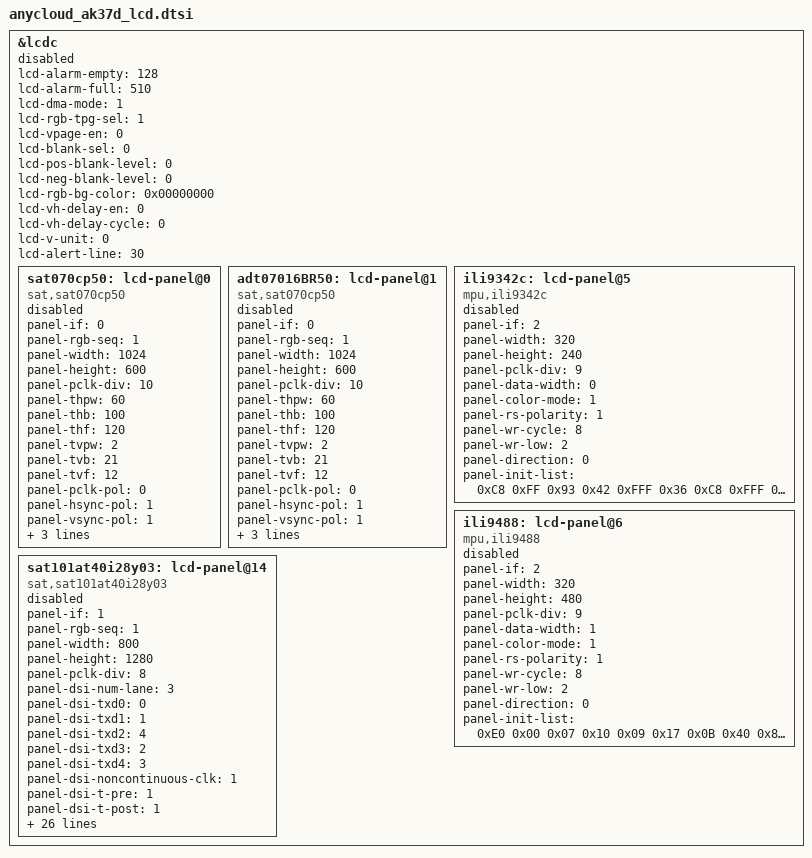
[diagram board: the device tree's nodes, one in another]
/*
 * AK37D LCD panel dts
 *
 * Copyright (C) 2018 Anyka(Guangzhou) Microelectronics Technology Co., Ltd.
 *
 * Author: Feilong Dong <dong_feilong@anyka.com>
 *
 * This program is free software; you can redistribute it and/or modify
 * it under the terms of the GNU General Public License as published by
 * the Free Software Foundation; either version 2 of the License, or
 * (at your option) any later version.
 *
 * This program is distributed in the hope that it will be useful,
 * but WITHOUT ANY WARRANTY; without even the implied warranty of
 * MERCHANTABILITY or FITNESS FOR A PARTICULAR PURPOSE.  See the
 * GNU General Public License for more details.
 */

&lcdc {
    lcd-alarm-empty = <128>;
    lcd-alarm-full = <510>;
    lcd-dma-mode = <1>;
    //lcd-dummy-seq = <0>; //for 8bit rgb panel set
    //lcd-rgb-seq-sel = <0>;
    //lcd-rgb-odd-seq = <0>;
    //lcd-rgb-even-seq = <0>;
    lcd-rgb-tpg-sel = <1>;
    lcd-vpage-en = <0>; //don't support vpage function in driver
    lcd-blank-sel = <0>;
    lcd-pos-blank-level = <0>;
    lcd-neg-blank-level = <0>;
    lcd-rgb-bg-color = <0x00000000>;
    lcd-vh-delay-en = <0>;
    lcd-vh-delay-cycle = <0>;
    lcd-v-unit = <0>;
    lcd-alert-line = <30>;
    status = "disable";
    
    sat070cp50: lcd-panel@0 { //for RGB panel setting
        compatible = "sat,sat070cp50";
        panel-if = <0>; //0 for RGB, 1 for MIPI, 2 for MPU
        panel-rgb-seq = <1>; //0 for BGR, 1 for RGB
        panel-width = <1024>;
        panel-height = <600>;
        panel-pclk-div = <10>; //pixel clock = Peri_pll/(pclk_div+1)
        panel-thpw = <60>;
        panel-thb = <100>;
        panel-thf = <120>;
        panel-tvpw = <2>;
        panel-tvb = <21>;
        panel-tvf = <12>;
        panel-pclk-pol = <0>; //0:pos, 1:neg
        panel-hsync-pol = <1>;
        panel-vsync-pol = <1>;
        panel-vogate-pol = <0>;
        panel-bus-width = <3>; //0:8bits,1:16bits,2:18bits,3:24bits
        panel-sync-mode = <1>; 

        status = "disable";
    };

    adt07016BR50: lcd-panel@1 { //for AJB RGB panel setting
        compatible = "sat,sat070cp50";
        panel-if = <0>; //0 for RGB, 1 for MIPI, 2 for MPU
        panel-rgb-seq = <1>; //0 for BGR, 1 for RGB
        panel-width = <1024>;
        panel-height = <600>;
        panel-pclk-div = <10>; //pixel clock = Peri_pll/(pclk_div+1)
        panel-thpw = <60>;
        panel-thb = <100>;
        panel-thf = <120>;
        panel-tvpw = <2>;
        panel-tvb = <21>;
        panel-tvf = <12>;
        panel-pclk-pol = <0>; //0:pos, 1:neg
        panel-hsync-pol = <1>;
        panel-vsync-pol = <1>;
        panel-vogate-pol = <0>;
        panel-bus-width = <3>; //0:8bits,1:16bits,2:18bits,3:24bits
        panel-sync-mode = <1>; 

        status = "disable";
    };

 /*
	//old mipi display
    sat101cp40: lcd-panel@2 { //for JD9365 MIPI panel setting
        compatible = "sat,sat101cp40";
        panel-if = <1>; //0 for RGB, 1 for MIPI, 2 for MPU
        panel-rgb-seq = <1>; //0 for BGR, 1 for RGB
        panel-width = <800>;
        panel-height = <1280>;
        panel-pclk-div = <8>; //pixel clock = Peri_pll/(pclk_div+1)
        panel-dsi-num-lane = <3>; //0-3: 1lane-4lane
        //0-3: data0-data3, 4: clk
        panel-dsi-txd0 = <0>;
        panel-dsi-txd1 = <1>;
        panel-dsi-txd2 = <4>;
        panel-dsi-txd3 = <2>;
        panel-dsi-txd4 = <3>;
        panel-dsi-noncontinuous-clk = <0>; //0:continuous,1:noncontinuous
        panel-dsi-t-pre = <1>; //t-pre, >=1
        panel-dsi-t-post = <1>; //t-post=tlpx+t-prepare+t-zero+t-pre, >=1
        panel-dsi-tx-gap = <1>; //ths-exit
        panel-dsi-autoinsert-eotp = <0>; //0:not insert,1:auto-insert
        panel-dsi-htx-to-count = <0xFFFFFF>; //high speed TX timeout count
        panel-dsi-lrx-to-count = <0xFFFFFF>; //Low power RX timeout count
        panel-dsi-bta-to-count = <0xFFFFFF>; //Bus turn around timeout count
        panel-dsi-t-wakeup = <0xc8>; //DPHY T-wakeup time
        panel-dsi-pix-fifo-send-level = <512>; //buffer send level <= 512
        //0-2:16-bit config 1-3; 3-4:18-bit config 1-2; 5:24-bit
        panel-dsi-if-color-coding = <0x05>;
        //0:16-bit;1:18-bit;2:18-bit loosely packed;3:24-bit
        panel-dsi-pix-format = <0x03>;
        panel-dsi-vsync-pol = <0>; //0:active low; 1:active high
        panel-dsi-hsync-pol = <0>; //0:active low; 1:active high
        //0:Non-burst mode with sync pulses;
        //1:Noe-burst mode with sync events;
        //2:Burst mode; 3:reserved
        panel-dsi-video-mode = <2>;
        panel-dsi-hfp = <40>; //H front porch blanking packet payload size in bytes
        panel-dsi-hbp = <20>; //H back porch blanking packet payload size in bytes
        panel-dsi-hsa = <20>; //H sync width blanking packet payload size in bytes
        panel-dsi-mult-pkts-en = <0>; //0: single packet;1: two packets
        panel-dsi-vbp = <8>; //V back porch lines
        panel-dsi-vfp = <8>; //V front porch lines
        panel-dsi-vsa = <4>;
        //0:blanking packets send during BLLP;1:LP mode used for BLLP
        panel-dsi-bllp-mode = <1>;
        panel-dsi-use-null-pkt-bllp = <0>; //0:blanking packet; 1:Null packet
        panel-dsi-vc = <0x00>; //Virtual channel
        panel-dsi-cmd-type = <0x0>; //0:send in LP mode, 1:send in HS mode
        panel-dsi-clk = <600>;
        //add special config list here
        panel-init-list =  //delay, type, data, parameters, end symbol
                          < 0x00 0x15 0xE0 0x00 0xFFF
                            0x00 0x15 0xE1 0x93 0xFFF
                            0x00 0x15 0xE2 0x65 0xFFF
                            0x00 0x15 0xE3 0xF8 0xFFF
                            0x00 0x15 0x80 0x03 0xFFF
                            0x00 0x15 0xE0 0x01 0xFFF
                            0x00 0x15 0x00 0x00 0xFFF
                            0x00 0x15 0x01 0x65 0xFFF
                            0x00 0x15 0x17 0x00 0xFFF
                            0x00 0x15 0x18 0xAF 0xFFF
                            0x00 0x15 0x19 0x01 0xFFF
                            0x00 0x15 0x1A 0x00 0xFFF
                            0x00 0x15 0x1B 0xAF 0xFFF
                            0x00 0x15 0x1C 0x01 0xFFF
                            0x00 0x15 0x1F 0x3E 0xFFF
                            0x00 0x15 0x20 0x28 0xFFF
                            0x00 0x15 0x21 0x28 0xFFF
                            0x00 0x15 0x22 0x7E 0xFFF
                            0x00 0x15 0x35 0x2A 0xFFF
                            0x00 0x15 0x37 0x09 0xFFF
                            0x00 0x15 0x38 0x04 0xFFF
                            0x00 0x15 0x39 0x00 0xFFF
                            0x00 0x15 0x3A 0x01 0xFFF
                            0x00 0x15 0x3C 0x76 0xFFF
                            0x00 0x15 0x3D 0xFF 0xFFF
                            0x00 0x15 0x3E 0xFF 0xFFF
                            0x00 0x15 0x3F 0x7F 0xFFF
                            0x00 0x15 0x40 0x06 0xFFF
                            0x00 0x15 0x41 0xA0 0xFFF
                            0x00 0x15 0x42 0x81 0xFFF
                            0x00 0x15 0x43 0x14 0xFFF
                            0x00 0x15 0x44 0x0A 0xFFF
                            0x00 0x15 0x45 0x12 0xFFF
                            0x00 0x15 0x55 0x01 0xFFF
                            0x00 0x15 0x56 0x01 0xFFF
                            0x00 0x15 0x57 0x6E 0xFFF
                            0x00 0x15 0x58 0x07 0xFFF
                            0x00 0x15 0x59 0x07 0xFFF
                            0x00 0x15 0x5A 0x29 0xFFF
                            0x00 0x15 0x5B 0x24 0xFFF
                            0x00 0x15 0x5D 0x7C 0xFFF
                            0x00 0x15 0x5E 0x65 0xFFF
                            0x00 0x15 0x5F 0x57 0xFFF
                            0x00 0x15 0x60 0x4A 0xFFF
                            0x00 0x15 0x61 0x46 0xFFF
                            0x00 0x15 0x62 0x36 0xFFF
                            0x00 0x15 0x63 0x3A 0xFFF
                            0x00 0x15 0x64 0x23 0xFFF
                            0x00 0x15 0x65 0x3A 0xFFF
                            0x00 0x15 0x66 0x38 0xFFF
                            0x00 0x15 0x67 0x38 0xFFF
                            0x00 0x15 0x68 0x55 0xFFF
                            0x00 0x15 0x69 0x43 0xFFF
                            0x00 0x15 0x6A 0x4A 0xFFF
                            0x00 0x15 0x6B 0x3B 0xFFF
                            0x00 0x15 0x6C 0x36 0xFFF
                            0x00 0x15 0x6D 0x28 0xFFF
                            0x00 0x15 0x6E 0x15 0xFFF
                            0x00 0x15 0x6F 0x00 0xFFF
                            0x00 0x15 0x70 0x7C 0xFFF
                            0x00 0x15 0x71 0x66 0xFFF
                            0x00 0x15 0x72 0x57 0xFFF
                            0x00 0x15 0x73 0x4A 0xFFF
                            0x00 0x15 0x74 0x46 0xFFF
                            0x00 0x15 0x75 0x36 0xFFF
                            0x00 0x15 0x76 0x3A 0xFFF
                            0x00 0x15 0x77 0x23 0xFFF
                            0x00 0x15 0x78 0x3A 0xFFF
                            0x00 0x15 0x79 0x38 0xFFF
                            0x00 0x15 0x7A 0x38 0xFFF
                            0x00 0x15 0x7B 0x55 0xFFF
                            0x00 0x15 0x7C 0x43 0xFFF
                            0x00 0x15 0x7D 0x4A 0xFFF
                            0x00 0x15 0x7E 0x3B 0xFFF
                            0x00 0x15 0x7F 0x36 0xFFF
                            0x00 0x15 0x80 0x28 0xFFF
                            0x00 0x15 0x81 0x15 0xFFF
                            0x00 0x15 0x82 0x00 0xFFF
                            0x00 0x15 0xE0 0x02 0xFFF
                            0x00 0x15 0x00 0x1E 0xFFF
                            0x00 0x15 0x01 0x1E 0xFFF
                            0x00 0x15 0x02 0x41 0xFFF
                            0x00 0x15 0x03 0x41 0xFFF
                            0x00 0x15 0x04 0x43 0xFFF
                            0x00 0x15 0x05 0x43 0xFFF
                            0x00 0x15 0x06 0x1F 0xFFF
                            0x00 0x15 0x07 0x1F 0xFFF
                            0x00 0x15 0x08 0x1F 0xFFF
                            0x00 0x15 0x09 0x1F 0xFFF
                            0x00 0x15 0x0A 0x1E 0xFFF
                            0x00 0x15 0x0B 0x1E 0xFFF
                            0x00 0x15 0x0C 0x1F 0xFFF
                            0x00 0x15 0x0D 0x47 0xFFF
                            0x00 0x15 0x0E 0x47 0xFFF
                            0x00 0x15 0x0F 0x45 0xFFF
                            0x00 0x15 0x10 0x45 0xFFF
                            0x00 0x15 0x11 0x4B 0xFFF
                            0x00 0x15 0x12 0x4B 0xFFF
                            0x00 0x15 0x13 0x49 0xFFF
                            0x00 0x15 0x14 0x49 0xFFF
                            0x00 0x15 0x15 0x1F 0xFFF
                            0x00 0x15 0x16 0x1E 0xFFF
                            0x00 0x15 0x17 0x1E 0xFFF
                            0x00 0x15 0x18 0x40 0xFFF
                            0x00 0x15 0x19 0x40 0xFFF
                            0x00 0x15 0x1A 0x42 0xFFF
                            0x00 0x15 0x1B 0x42 0xFFF
                            0x00 0x15 0x1C 0x1F 0xFFF
                            0x00 0x15 0x1D 0x1F 0xFFF
                            0x00 0x15 0x1E 0x1F 0xFFF
                            0x00 0x15 0x1F 0x1F 0xFFF
                            0x00 0x15 0x20 0x1E 0xFFF
                            0x00 0x15 0x21 0x1E 0xFFF
                            0x00 0x15 0x22 0x1f 0xFFF
                            0x00 0x15 0x23 0x46 0xFFF
                            0x00 0x15 0x24 0x46 0xFFF
                            0x00 0x15 0x25 0x44 0xFFF
                            0x00 0x15 0x26 0x44 0xFFF
                            0x00 0x15 0x27 0x4A 0xFFF
                            0x00 0x15 0x28 0x4A 0xFFF
                            0x00 0x15 0x29 0x48 0xFFF
                            0x00 0x15 0x2A 0x48 0xFFF
                            0x00 0x15 0x2B 0x1F 0xFFF
                            0x00 0x15 0x2C 0x11 0xFFF
                            0x00 0x15 0x2D 0x0F 0xFFF
                            0x00 0x15 0x2E 0x0D 0xFFF
                            0x00 0x15 0x2F 0x0B 0xFFF
                            0x00 0x15 0x30 0x09 0xFFF
                            0x00 0x15 0x31 0x07 0xFFF
                            0x00 0x15 0x32 0x05 0xFFF
                            0x00 0x15 0x33 0x18 0xFFF
                            0x00 0x15 0x34 0x17 0xFFF
                            0x00 0x15 0x35 0x1F 0xFFF
                            0x00 0x15 0x36 0x01 0xFFF
                            0x00 0x15 0x37 0x1F 0xFFF
                            0x00 0x15 0x38 0x1F 0xFFF
                            0x00 0x15 0x39 0x1F 0xFFF
                            0x00 0x15 0x3A 0x1F 0xFFF
                            0x00 0x15 0x3B 0x1F 0xFFF
                            0x00 0x15 0x3C 0x1F 0xFFF
                            0x00 0x15 0x3D 0x1F 0xFFF
                            0x00 0x15 0x3E 0x1F 0xFFF
                            0x00 0x15 0x3F 0x13 0xFFF
                            0x00 0x15 0x40 0x1F 0xFFF
                            0x00 0x15 0x41 0x1F 0xFFF
                            0x00 0x15 0x42 0x10 0xFFF
                            0x00 0x15 0x43 0x0E 0xFFF
                            0x00 0x15 0x44 0x0C 0xFFF
                            0x00 0x15 0x45 0x0A 0xFFF
                            0x00 0x15 0x46 0x08 0xFFF
                            0x00 0x15 0x47 0x06 0xFFF
                            0x00 0x15 0x48 0x04 0xFFF
                            0x00 0x15 0x49 0x18 0xFFF
                            0x00 0x15 0x4A 0x17 0xFFF
                            0x00 0x15 0x4B 0x1F 0xFFF
                            0x00 0x15 0x4C 0x00 0xFFF
                            0x00 0x15 0x4D 0x1F 0xFFF
                            0x00 0x15 0x4E 0x1F 0xFFF
                            0x00 0x15 0x4F 0x1F 0xFFF
                            0x00 0x15 0x50 0x1F 0xFFF
                            0x00 0x15 0x51 0x1F 0xFFF
                            0x00 0x15 0x52 0x1F 0xFFF
                            0x00 0x15 0x53 0x1F 0xFFF
                            0x00 0x15 0x54 0x1F 0xFFF
                            0x00 0x15 0x55 0x12 0xFFF
                            0x00 0x15 0x56 0x1F 0xFFF
                            0x00 0x15 0x57 0x1F 0xFFF
                            0x00 0x15 0x58 0x10 0xFFF
                            0x00 0x15 0x59 0x00 0xFFF
                            0x00 0x15 0x5A 0x00 0xFFF
                            0x00 0x15 0x5B 0x30 0xFFF
                            0x00 0x15 0x5C 0x03 0xFFF
                            0x00 0x15 0x5D 0x30 0xFFF
                            0x00 0x15 0x5E 0x01 0xFFF
                            0x00 0x15 0x5F 0x02 0xFFF
                            0x00 0x15 0x60 0x30 0xFFF
                            0x00 0x15 0x61 0x01 0xFFF
                            0x00 0x15 0x62 0x02 0xFFF
                            0x00 0x15 0x63 0x14 0xFFF
                            0x00 0x15 0x64 0x6A 0xFFF
                            0x00 0x15 0x65 0x05 0xFFF
                            0x00 0x15 0x66 0x12 0xFFF
                            0x00 0x15 0x67 0x73 0xFFF
                            0x00 0x15 0x68 0x05 0xFFF
                            0x00 0x15 0x69 0x14 0xFFF
                            0x00 0x15 0x6A 0x6A 0xFFF
                            0x00 0x15 0x6B 0x09 0xFFF
                            0x00 0x15 0x6C 0x00 0xFFF
                            0x00 0x15 0x6D 0x04 0xFFF
                            0x00 0x15 0x6E 0x02 0xFFF
                            0x00 0x15 0x6F 0x40 0xFFF
                            0x00 0x15 0x70 0x00 0xFFF
                            0x00 0x15 0x71 0x00 0xFFF
                            0x00 0x15 0x72 0x06 0xFFF
                            0x00 0x15 0x73 0x7B 0xFFF
                            0x00 0x15 0x74 0x00 0xFFF
                            0x00 0x15 0x75 0x07 0xFFF
                            0x00 0x15 0x76 0x00 0xFFF
                            0x00 0x15 0x77 0x5D 0xFFF
                            0x00 0x15 0x78 0x17 0xFFF
                            0x00 0x15 0x79 0x1F 0xFFF
                            0x00 0x15 0x7A 0x00 0xFFF
                            0x00 0x15 0x7B 0x00 0xFFF
                            0x00 0x15 0x7C 0x00 0xFFF
                            0x00 0x15 0x7D 0x03 0xFFF
                            0x00 0x15 0x7E 0x7B 0xFFF
                            0x00 0x15 0xE0 0x04 0xFFF
                            0x00 0x15 0x2B 0x2B 0xFFF
                            0x00 0x15 0x2E 0x44 0xFFF
                            0x00 0x15 0x09 0x11 0xFFF
                            0x00 0x15 0x2D 0x03 0xFFF
                            0x00 0x15 0x0E 0x48 0xFFF
                            0x00 0x15 0xE0 0x00 0xFFF
                            0x00 0x15 0xE6 0x02 0xFFF
                            0xC8 0x15 0xE7 0x02 0xFFF
                            0x78 0x05 0x11 0x00 0xFFF
                            0x64 0x05 0x29 0x00 0xFFF
                            0x00 0x15 0x35 0x00 0xFFF>;

        status = "disable";
    };
*/
/*    
    sat101at40: lcd-panel@3 { //for JD9364 MIPI panel setting
        compatible = "sat,sat101at40";
        panel-if = <1>; //0 for RGB, 1 for MIPI, 2 for MPU
        panel-rgb-seq = <1>; //0 for BGR, 1 for RGB
        panel-width = <800>;
        panel-height = <1280>;
        panel-pclk-div = <8>; //pixel clock = Peri_pll/(pclk_div+1)
        panel-dsi-num-lane = <3>; //0-3: 1lane-4lane
        //0-3: data0-data3, 4: clk
        panel-dsi-txd0 = <2>;
        panel-dsi-txd1 = <1>;
        panel-dsi-txd2 = <4>;
        panel-dsi-txd3 = <0>;
        panel-dsi-txd4 = <3>;
        panel-dsi-noncontinuous-clk = <0>; //0:continuous,1:noncontinuous
        panel-dsi-t-pre = <1>; //t-pre, >=1
        panel-dsi-t-post = <1>; //t-post=tlpx+t-prepare+t-zero+t-pre, >=1
        panel-dsi-tx-gap = <1>; //ths-exit
        panel-dsi-autoinsert-eotp = <0>; //0:not insert,1:auto-insert
        panel-dsi-htx-to-count = <0xFFFFFF>; //high speed TX timeout count
        panel-dsi-lrx-to-count = <0xFFFFFF>; //Low power RX timeout count
        panel-dsi-bta-to-count = <0xFFFFFF>; //Bus turn around timeout count
        panel-dsi-t-wakeup = <0xc8>; //DPHY T-wakeup time
        panel-dsi-pix-fifo-send-level = <512>; //buffer send level <= 512
        //0-2:16-bit config 1-3; 3-4:18-bit config 1-2; 5:24-bit
        panel-dsi-if-color-coding = <0x05>;
        //0:16-bit;1:18-bit;2:18-bit loosely packed;3:24-bit
        panel-dsi-pix-format = <0x03>;
        panel-dsi-vsync-pol = <0>; //0:active low; 1:active high
        panel-dsi-hsync-pol = <0>; //0:active low; 1:active high
        //0:Non-burst mode with sync pulses;
        //1:Noe-burst mode with sync events;
        //2:Burst mode; 3:reserved
        panel-dsi-video-mode = <2>;
        panel-dsi-hfp = <32>; //H front porch blanking packet payload size in bytes
        panel-dsi-hbp = <8>; //H back porch blanking packet payload size in bytes
        panel-dsi-hsa = <8>; //H sync width blanking packet payload size in bytes
        panel-dsi-mult-pkts-en = <0>; //0: single packet;1: two packets
        panel-dsi-vbp = <8>; //V back porch lines
        panel-dsi-vfp = <30>; //V front porch lines
        panel-dsi-vsa = <4>;
        //0:blanking packets send during BLLP;1:LP mode used for BLLP
        panel-dsi-bllp-mode = <1>;
        panel-dsi-use-null-pkt-bllp = <0>; //0:blanking packet; 1:Null packet
        panel-dsi-vc = <0x00>; //Virtual channel
        panel-dsi-cmd-type = <0x0>; //0:send in LP mode, 1:send in HS mode
        panel-dsi-clk = <600>;
        //add special config list here
        panel-init-list = <0x00 0x23 0xE0 0x00 0xFFF
                            0x00 0x23 0xE1 0x93 0xFFF
                            0x00 0x23 0xE2 0x65 0xFFF
                            0x00 0x23 0xE3 0xF8 0xFFF
                            0x00 0x23 0x70 0x10 0xFFF
                            0x00 0x23 0x71 0x13 0xFFF
                            0x00 0x23 0x72 0x06 0xFFF
                            0x00 0x23 0x80 0x03 0xFFF
                            0x00 0x23 0xE0 0x04 0xFFF
                            0x00 0x23 0x2D 0x03 0xFFF
                            0x00 0x23 0xE0 0x01 0xFFF
                            0x00 0x23 0x00 0x00 0xFFF
                            0x00 0x23 0x01 0xB3 0xFFF
                            0x00 0x23 0x17 0x00 0xFFF
                            0x00 0x23 0x18 0xD8 0xFFF
                            0x00 0x23 0x19 0x05 0xFFF
                            0x00 0x23 0x1A 0x00 0xFFF
                            0x00 0x23 0x1B 0xD8 0xFFF
                            0x00 0x23 0x1C 0x05 0xFFF
                            0x00 0x23 0x1F 0x7E 0xFFF
                            0x00 0x23 0x20 0x28 0xFFF
                            0x00 0x23 0x21 0x28 0xFFF
                            0x00 0x23 0x22 0x0E 0xFFF
                            0x00 0x23 0x24 0xF8 0xFFF
                            0x00 0x23 0x26 0xF3 0xFFF
                            0x00 0x23 0x27 0x44 0xFFF
                            0x00 0x23 0x37 0x59 0xFFF
                            0x00 0x23 0x38 0x05 0xFFF
                            0x00 0x23 0x39 0x0C 0xFFF
                            0x00 0x23 0x3A 0x18 0xFFF
                            0x00 0x23 0x3C 0x78 0xFFF
                            0x00 0x23 0x3E 0x78 0xFFF
                            0x00 0x23 0x40 0x06 0xFFF
                            0x00 0x23 0x41 0xA0 0xFFF
                            0x00 0x23 0x55 0x01 0xFFF
                            0x00 0x23 0x56 0x01 0xFFF
                            0x00 0x23 0x57 0xA8 0xFFF
                            0x00 0x23 0x58 0x0A 0xFFF
                            0x00 0x23 0x59 0x2A 0xFFF
                            0x00 0x23 0x5A 0x3C 0xFFF
                            0x00 0x23 0x5B 0x14 0xFFF
                            0x00 0x23 0x5D 0x70 0xFFF
                            0x00 0x23 0x5E 0x53 0xFFF
                            0x00 0x23 0x5F 0x42 0xFFF
                            0x00 0x23 0x60 0x35 0xFFF
                            0x00 0x23 0x61 0x32 0xFFF
                            0x00 0x23 0x62 0x23 0xFFF
                            0x00 0x23 0x63 0x28 0xFFF
                            0x00 0x23 0x64 0x13 0xFFF
                            0x00 0x23 0x65 0x2D 0xFFF
                            0x00 0x23 0x66 0x2D 0xFFF
                            0x00 0x23 0x67 0x2D 0xFFF
                            0x00 0x23 0x68 0x4B 0xFFF
                            0x00 0x23 0x69 0x39 0xFFF
                            0x00 0x23 0x6A 0x40 0xFFF
                            0x00 0x23 0x6B 0x2F 0xFFF
                            0x00 0x23 0x6C 0x26 0xFFF
                            0x00 0x23 0x6D 0x1E 0xFFF
                            0x00 0x23 0x6E 0x07 0xFFF
                            0x00 0x23 0x6F 0x02 0xFFF
                            0x00 0x23 0x70 0x70 0xFFF
                            0x00 0x23 0x71 0x53 0xFFF
                            0x00 0x23 0x72 0x42 0xFFF
                            0x00 0x23 0x73 0x35 0xFFF
                            0x00 0x23 0x74 0x32 0xFFF
                            0x00 0x23 0x75 0x23 0xFFF
                            0x00 0x23 0x76 0x28 0xFFF
                            0x00 0x23 0x77 0x13 0xFFF
                            0x00 0x23 0x78 0x2D 0xFFF
                            0x00 0x23 0x79 0x2D 0xFFF
                            0x00 0x23 0x7A 0x2D 0xFFF
                            0x00 0x23 0x7B 0x4B 0xFFF
                            0x00 0x23 0x7C 0x39 0xFFF
                            0x00 0x23 0x7D 0x40 0xFFF
                            0x00 0x23 0x7E 0x2F 0xFFF
                            0x00 0x23 0x7F 0x26 0xFFF
                            0x00 0x23 0x80 0x1E 0xFFF
                            0x00 0x23 0x81 0x07 0xFFF
                            0x00 0x23 0x82 0x02 0xFFF
                            0x00 0x23 0xE0 0x02 0xFFF
                            0x00 0x23 0x00 0x53 0xFFF
                            0x00 0x23 0x01 0x5F 0xFFF
                            0x00 0x23 0x02 0x5F 0xFFF
                            0x00 0x23 0x03 0x5F 0xFFF
                            0x00 0x23 0x04 0x5F 0xFFF
                            0x00 0x23 0x05 0x51 0xFFF
                            0x00 0x23 0x06 0x58 0xFFF
                            0x00 0x23 0x07 0x57 0xFFF
                            0x00 0x23 0x08 0x4F 0xFFF
                            0x00 0x23 0x09 0x5F 0xFFF
                            0x00 0x23 0x0A 0x4D 0xFFF
                            0x00 0x23 0x0B 0x4B 0xFFF
                            0x00 0x23 0x0C 0x5F 0xFFF
                            0x00 0x23 0x0D 0x49 0xFFF
                            0x00 0x23 0x0E 0x47 0xFFF
                            0x00 0x23 0x0F 0x45 0xFFF
                            0x00 0x23 0x10 0x41 0xFFF
                            0x00 0x23 0x11 0x5F 0xFFF
                            0x00 0x23 0x12 0x5F 0xFFF
                            0x00 0x23 0x13 0x5F 0xFFF
                            0x00 0x23 0x14 0x5F 0xFFF
                            0x00 0x23 0x15 0x5F 0xFFF
                            0x00 0x23 0x16 0x52 0xFFF
                            0x00 0x23 0x17 0x5F 0xFFF
                            0x00 0x23 0x18 0x5F 0xFFF
                            0x00 0x23 0x19 0x5F 0xFFF
                            0x00 0x23 0x1A 0x5F 0xFFF
                            0x00 0x23 0x1B 0x50 0xFFF
                            0x00 0x23 0x1C 0x58 0xFFF
                            0x00 0x23 0x1D 0x57 0xFFF
                            0x00 0x23 0x1E 0x4E 0xFFF
                            0x00 0x23 0x1F 0x5F 0xFFF
                            0x00 0x23 0x20 0x4C 0xFFF
                            0x00 0x23 0x21 0x4A 0xFFF
                            0x00 0x23 0x22 0x5F 0xFFF
                            0x00 0x23 0x23 0x48 0xFFF
                            0x00 0x23 0x24 0x46 0xFFF
                            0x00 0x23 0x25 0x44 0xFFF
                            0x00 0x23 0x26 0x40 0xFFF
                            0x00 0x23 0x27 0x5F 0xFFF
                            0x00 0x23 0x28 0x5F 0xFFF
                            0x00 0x23 0x29 0x5F 0xFFF
                            0x00 0x23 0x2A 0x5F 0xFFF
                            0x00 0x23 0x2B 0x5F 0xFFF
                            0x00 0x23 0x2C 0x52 0xFFF
                            0x00 0x23 0x2D 0x5F 0xFFF
                            0x00 0x23 0x2E 0x5F 0xFFF
                            0x00 0x23 0x2F 0x5F 0xFFF
                            0x00 0x23 0x30 0x5F 0xFFF
                            0x00 0x23 0x31 0x40 0xFFF
                            0x00 0x23 0x32 0x58 0xFFF
                            0x00 0x23 0x33 0x57 0xFFF
                            0x00 0x23 0x34 0x44 0xFFF
                            0x00 0x23 0x35 0x5F 0xFFF
                            0x00 0x23 0x36 0x46 0xFFF
                            0x00 0x23 0x37 0x48 0xFFF
                            0x00 0x23 0x38 0x5F 0xFFF
                            0x00 0x23 0x39 0x4A 0xFFF
                            0x00 0x23 0x3A 0x4C 0xFFF
                            0x00 0x23 0x3B 0x4E 0xFFF
                            0x00 0x23 0x3C 0x50 0xFFF
                            0x00 0x23 0x3D 0x5F 0xFFF
                            0x00 0x23 0x3E 0x5F 0xFFF
                            0x00 0x23 0x3F 0x5F 0xFFF
                            0x00 0x23 0x40 0x5F 0xFFF
                            0x00 0x23 0x41 0x5F 0xFFF
                            0x00 0x23 0x42 0x53 0xFFF
                            0x00 0x23 0x43 0x5F 0xFFF
                            0x00 0x23 0x44 0x5F 0xFFF
                            0x00 0x23 0x45 0x5F 0xFFF
                            0x00 0x23 0x46 0x5F 0xFFF
                            0x00 0x23 0x47 0x41 0xFFF
                            0x00 0x23 0x48 0x58 0xFFF
                            0x00 0x23 0x49 0x57 0xFFF
                            0x00 0x23 0x4A 0x45 0xFFF
                            0x00 0x23 0x4B 0x5F 0xFFF
                            0x00 0x23 0x4C 0x47 0xFFF
                            0x00 0x23 0x4D 0x49 0xFFF
                            0x00 0x23 0x4E 0x5F 0xFFF
                            0x00 0x23 0x4F 0x4B 0xFFF
                            0x00 0x23 0x50 0x4D 0xFFF
                            0x00 0x23 0x51 0x4F 0xFFF
                            0x00 0x23 0x52 0x51 0xFFF
                            0x00 0x23 0x53 0x5F 0xFFF
                            0x00 0x23 0x54 0x5F 0xFFF
                            0x00 0x23 0x55 0x5F 0xFFF
                            0x00 0x23 0x56 0x5F 0xFFF
                            0x00 0x23 0x57 0x5F 0xFFF
                            0x00 0x23 0x58 0x10 0xFFF
                            0x00 0x23 0x59 0x00 0xFFF
                            0x00 0x23 0x5A 0x00 0xFFF
                            0x00 0x23 0x5B 0x10 0xFFF
                            0x00 0x23 0x5C 0x05 0xFFF
                            0x00 0x23 0x5D 0x30 0xFFF
                            0x00 0x23 0x5E 0x00 0xFFF
                            0x00 0x23 0x5F 0x00 0xFFF
                            0x00 0x23 0x60 0x30 0xFFF
                            0x00 0x23 0x61 0x02 0xFFF
                            0x00 0x23 0x62 0x00 0xFFF
                            0x00 0x23 0x63 0x03 0xFFF
                            0x00 0x23 0x64 0x7B 0xFFF
                            0x00 0x23 0x65 0x75 0xFFF
                            0x00 0x23 0x66 0x0B 0xFFF
                            0x00 0x23 0x67 0xB3 0xFFF
                            0x00 0x23 0x68 0x07 0xFFF
                            0x00 0x23 0x69 0x06 0xFFF
                            0x00 0x23 0x6A 0x7B 0xFFF
                            0x00 0x23 0x6B 0x04 0xFFF
                            0x00 0x23 0x6C 0x00 0xFFF
                            0x00 0x23 0x6D 0x04 0xFFF
                            0x00 0x23 0x6E 0x04 0xFFF
                            0x00 0x23 0x6F 0x88 0xFFF
                            0x00 0x23 0x70 0x00 0xFFF
                            0x00 0x23 0x71 0x00 0xFFF
                            0x00 0x23 0x72 0x06 0xFFF
                            0x00 0x23 0x73 0x7B 0xFFF
                            0x00 0x23 0x74 0x00 0xFFF
                            0x00 0x23 0x75 0x80 0xFFF
                            0x00 0x23 0x76 0x00 0xFFF
                            0x00 0x23 0x77 0x0D 0xFFF
                            0x00 0x23 0x78 0x2A 0xFFF
                            0x00 0x23 0x79 0x00 0xFFF
                            0x00 0x23 0x7A 0x00 0xFFF
                            0x00 0x23 0x7B 0x00 0xFFF
                            0x00 0x23 0x7C 0x00 0xFFF
                            0x00 0x23 0x7D 0x03 0xFFF
                            0x00 0x23 0x7E 0x7B 0xFFF
                            0x00 0x23 0xE0 0x00 0xFFF
                            0x78 0x13 0x11 0x00 0xFFF
                            0x05 0x13 0x29 0x00 0xFFF
                            0x78 0x23 0x35 0x00 0xFFF>;

        status = "disable";
    };
*/
/*    am1080wq05: lcd-panel@4 { //for am MIPI panel setting
        compatible = "am,am1080wq05";
        panel-if = <1>; //0 for RGB, 1 for MIPI, 2 for MPU
        panel-rgb-seq = <1>; //0 for BGR, 1 for RGB
        panel-width = <800>;
        panel-height = <1280>;
        panel-pclk-div = <7>; //pixel clock = Peri_pll/(pclk_div+1)
        panel-dsi-num-lane = <3>; //0-3: 1lane-4lane
        //0-3: data0-data3, 4: clk
        panel-dsi-txd0 = <0>;
        panel-dsi-txd1 = <1>;
        panel-dsi-txd2 = <4>;
        panel-dsi-txd3 = <2>;
        panel-dsi-txd4 = <3>;
        panel-dsi-noncontinuous-clk = <0>; //0:continuous,1:noncontinuous
        panel-dsi-t-pre = <1>; //t-pre, >=1
        panel-dsi-t-post = <1>; //t-post=tlpx+t-prepare+t-zero+t-pre, >=1
        panel-dsi-tx-gap = <1>; //ths-exit, >=1
        panel-dsi-autoinsert-eotp = <0>; //0:not insert,1:auto-insert
        //panel-dsi-htx-to-count = <0xFFFFFF>; //high speed TX timeout count
        //panel-dsi-lrx-to-count = <0xFFFFFF>; //Low power RX timeout count
        //panel-dsi-bta-to-count = <0xFFFFFF>; //Bus turn around timeout count
        panel-dsi-t-wakeup = <0xc8>; //DPHY T-wakeup time
        panel-dsi-pix-fifo-send-level = <512>; //buffer send level
        //0-2:16-bit config 1-3; 3-4:18-bit config 1-2; 5:24-bit
        panel-dsi-if-color-coding = <0x05>;
        //0:16-bit;1:18-bit;2:18-bit loosely packed;3:24-bit
        panel-dsi-pix-format = <0x03>;
        panel-dsi-vsync-pol = <1>; //0:active low; 1:active high
        panel-dsi-hsync-pol = <1>; //0:active low; 1:active high
        //0:Non-burst mode with sync pulses;
        //1:Noe-burst mode with sync events;
        //2:Burst mode; 3:reserved
        panel-dsi-video-mode = <2>;
        panel-dsi-hfp = <16>; //H front porch blanking packet payload size in bytes
        panel-dsi-hbp = <59>; //H back porch blanking packet payload size in bytes
        panel-dsi-hsa = <5>; //H sync width blanking packet payload size in bytes
        panel-dsi-mult-pkts-en = <0>; //0: single packet;1: two packets
        panel-dsi-vbp = <3>; //V back porch lines
        panel-dsi-vfp = <8>; //V front porch lines
        panel-dsi-vsa = <5>;
        //0:blanking packets send during BLLP;1:LP mode used for BLLP
        panel-dsi-bllp-mode = <1>;
        panel-dsi-use-null-pkt-bllp = <0>; //0:blanking packet; 1:Null packet
        panel-dsi-vc = <0x00>; //Virtual channel
        panel-dsi-cmd-type = <0x0>; //0:send in LP mode, 1:send in HS mode
        panel-dsi-clk = <450>;
        //add special config list here
        panel-init-list = <0x00 0x39 0xF0 0x5A 0x5A 0xFFF //delay, type, data, end symbol
                           0x00 0x39 0xF1 0x5A 0x5A 0xFFF
                           0x00 0x39 0xFC 0xA5 0xA5 0xFFF
                           0x00 0x39 0xD0 0x00 0x10 0xFFF
                           0x00 0x39 0xB1 0x10 0xFFF
                           0x00 0x39 0xB2 0x14 0x22 0x2F
                                     0x04 0xFFF
                           0x00 0x39 0xB5 0x01 0xFFF
                           0x00 0x39 0xEE 0x00 0x00 0x1F
                                     0x00 0x00 0x00 0x1F
                                     0x00 0xFFF
                           0x00 0x39 0xEF 0x56 0x34 0x43
                                     0x65 0x90 0x80 0x24
                                     0x80 0x00 0x91 0x11
                                     0x11 0x11 0xFFF
                           0x00 0x39 0xF7 0x04 0x08 0x09
                                     0x0A 0x0B 0x0C 0x0D
                                     0x0E 0x0F 0x16 0x17
                                     0x10 0x01 0x01 0x01
                                     0x01 0x04 0x08 0x09
                                     0x0A 0x0B 0x0C 0x0D
                                     0x0E 0x0F 0x16 0x17
                                     0x10 0x01 0x01 0x01
                                     0x01 0xFFF
                           0x00 0x39 0xF2 0x02 0x08 0x08
                                     0x40 0x10 0xFFF
                           0x00 0x39 0xF6 0x60 0x25 0x26
                                     0x00 0x00 0x00 0xFFF
                           0x00 0x39 0xFA 0x04 0x35 0x07
                                     0x0B 0x12 0x0B 0x10
                                     0x16 0x1A 0x24 0x2C
                                     0x33 0x3B 0x3B 0x33
                                     0x34 0x33 0xFFF
                           0x00 0x39 0xFB 0x04 0x35 0x07
                                     0x0B 0x12 0x0B 0x10
                                     0x16 0x1A 0x24 0x2C
                                     0x33 0x3B 0x3B 0x33
                                     0x34 0x33 0xFFF
                           0x00 0x39 0xF3 0x01 0xC4 0xE0
                                     0x62 0xD4 0x83 0x37
                                     0x3C 0x24 0x00 0xFFF
                           0x00 0x39 0xF4 0x00 0x02 0x03
                                     0x26 0x03 0x02 0x09
                                     0x00 0x07 0x16 0x16
                                     0x03 0x00 0x08 0x08
                                     0x03 0x19 0x1C 0x12
                                     0x1C 0x1D 0x1E 0x1A
                                     0x09 0x01 0x04 0x02
                                     0x61 0x74 0x75 0x72
                                     0x83 0x80 0x80 0xF0
                                     0xFFF
                           0x00 0x39 0xB0 0x01 0xFFF
                           0x00 0x39 0xF5 0x2F 0x2F 0x5F
                                     0xAB 0x98 0x52 0x0F
                                     0x33 0x43 0x04 0x59
                                     0x54 0x52 0x05 0x40
                                     0x40 0x5D 0x59 0x40 0xFFF
                           0x00 0x39 0xBC 0x01 0x4E 0x08 0xFFF
                           0x00 0x39 0xE1 0x03 0x10 0x1C
                                     0xA0 0x10 0xFFF
                           0x00 0x39 0xFD 0x16 0x10 0x11
                                     0x20 0x09 0xFFF
                           0x00 0x39 0x35 0x00 0xFFF
                           0x1E 0x39 0x11 0x00 0xFFF
                           0x96 0x39 0xC3 0x40 0x00 0x28 0xFFF
                           0xC8 0x39 0x29 0x00 0xFFF>;

        status = "disable";
    };
*/
    ili9342c: lcd-panel@5 {
		compatible = "mpu,ili9342c";
		panel-if = <2>;//0 for RGB, 1 for MIPI, 2 for MPU
		panel-width = <320>;
		panel-height = <240>;
		panel-pclk-div = <9>; //default pixel clock = Peri_pll(600M)/(pclk_div+1)=60M
		panel-data-width = <0>; //0:8bits,1:16bits,2:18bits,3:9bits
		panel-color-mode = <1>; //0:4K 1:64K/256K
		panel-rs-polarity = <1>; //0:negative(0 means data while 1 means command)
								//1:positive(0 means command while 1 means data)
		panel-wr-cycle = <8>; // write timing setting, wr-cycle >= 4*(wr-low) (8/9bits mode)
		panel-wr-low = <2>; // write timing setting,wr_cycle_len/2 - wr_low_len >= 2 (8/9bits mode)

    /* 0 for portrait, 1 for landscape*/
		panel-direction = <0>;

    panel-init-list = <0xC8 0xFF 0x93 0x42 0xFFF
                             0x36 0xC8 0xFFF
                             0x3A 0x55 0xFFF
                             0xC0 0x13 0x0E 0xFFF
                             0xC1 0x02 0xFFF
                             0xC5 0xD5 0xFFF
                             0xB1 0x00 0x1B 0xFFF
                             0xB4 0x02 0xFFF
                             0xE0 0x00 0x07 0x0C 0x06
                             0x15 0x09 0x3A 0x36 0x48
                             0x02 0x0B 0x0A 0x15 0x16
                             0x0F 0xFFF
                             0xE1 0x00 0x25 0x26 0x02
                             0x0E 0x03 0x3D 0x13 0x4E
                             0x03 0x0E 0x0B 0x34 0x37
                             0x0F 0xFFF
                             0x11 0xFFF
                             0x29 0xFFF>;
	 	    status = "disable";
    };

    ili9488: lcd-panel@6 {
		compatible = "mpu,ili9488";
		panel-if = <2>;//0 for RGB, 1 for MIPI, 2 for MPU
		panel-width = <320>;
		panel-height = <480>;
		panel-pclk-div = <9>; //default pixel clock = Peri_pll(600M)/(pclk_div+1)=60M
		panel-data-width = <1>; //0:8bits,1:16bits,2:18bits,3:9bits
		panel-color-mode = <1>; //0:4K 1:64K/256K
		panel-rs-polarity = <1>; //0:negative(0 means data while 1 means command)
								//1:positive(0 means command while 1 means data)
		panel-wr-cycle = <8>; // write timing setting, wr-cycle >= 4*(wr-low) (8/9bits mode)
		panel-wr-low = <2>; // write timing setting,wr_cycle_len/2 - wr_low_len >= 2 (8/9bits mode)

    /* 0 for portrait, 1 for landscape*/
		panel-direction = <0>;

		panel-init-list = <0xE0 0x00 0x07 0x10 0x09
						   0x17 0x0B 0x40 0x8A 0x4B
						   0x0A 0x0D 0x0F 0x15 0x16
                           0x0F 0xFFF
                           0xE1 0x00 0x1A 0x1B 0x02
						   0x0D 0x05 0x30 0x35 0x43
						   0x02 0x0A 0x09 0x32 0x36
						   0x0F 0xFFF
						   0xB1 0xA0 0xFFF
						   0xB4 0x02 0xFFF
						   0xC0 0x17 0x15 0xFFF
						   0xC1 0x41 0xFFF
						   0xC5 0x00 0x30 0x80 0xFFF
						   0xB6 0x02 0xFFF
						   0x36 0x48 0xFFF
						   0x3A 0x55 0xFFF
						   0xE9 0x00 0xFFF
						   0xF7 0xA9 0x51 0x2C 0x82 0xFFF
						   0x11 0xFFF
 						   0x29 0xFFF>;

 	    status = "disable";
    };

/*
    adi10107bm40_jd9365da: lcd-panel@7 { //for JD9365DA MIPI panel setting
        compatible = "adi,adi10107bm40_jd9365da";
        panel-if = <1>; //0 for RGB, 1 for MIPI, 2 for MPU
        panel-rgb-seq = <1>; //0 for BGR, 1 for RGB
        panel-width = <800>;
        panel-height = <1280>;
        panel-pclk-div = <10>; //pixel clock = Peri_pll/(pclk_div+1)
        panel-dsi-num-lane = <3>; //0-3: 1lane-4lane
        //0-3: data0-data3, 4: clk
        panel-dsi-txd0 = <0>;
        panel-dsi-txd1 = <1>;
        panel-dsi-txd2 = <4>;
        panel-dsi-txd3 = <2>;
        panel-dsi-txd4 = <3>;
	//This Driver IC must be working in noncontinous
        panel-dsi-noncontinuous-clk = <1>; //0:continuous,1:noncontinuous
        panel-dsi-t-pre = <1>; //t-pre, >=1
        panel-dsi-t-post = <1>; //t-post=tlpx+t-prepare+t-zero+t-pre, >=1
        panel-dsi-tx-gap = <1>; //ths-exit
        panel-dsi-autoinsert-eotp = <0>; //0:not insert,1:auto-insert
        panel-dsi-htx-to-count = <0xFFFFFF>; //high speed TX timeout count
        panel-dsi-lrx-to-count = <0xFFFFFF>; //Low power RX timeout count
        panel-dsi-bta-to-count = <0xFFFFFF>; //Bus turn around timeout count
        panel-dsi-t-wakeup = <0xc8>; //DPHY T-wakeup time
        panel-dsi-pix-fifo-send-level = <512>; //buffer send level <= 512
        //0-2:16-bit config 1-3; 3-4:18-bit config 1-2; 5:24-bit
        panel-dsi-if-color-coding = <0x05>;
        //0:16-bit;1:18-bit;2:18-bit loosely packed;3:24-bit
        panel-dsi-pix-format = <0x03>;
        panel-dsi-vsync-pol = <0>; //0:active low; 1:active high
        panel-dsi-hsync-pol = <0>; //0:active low; 1:active high
        //0:Non-burst mode with sync pulses;
        //1:Noe-burst mode with sync events;
        //2:Burst mode; 3:reserved
        panel-dsi-video-mode = <2>;
        panel-dsi-hfp = <40>; //H front porch blanking packet payload size in bytes
        panel-dsi-hbp = <20>; //H back porch blanking packet payload size in bytes
        panel-dsi-hsa = <20>; //H sync width blanking packet payload size in bytes
        panel-dsi-mult-pkts-en = <0>; //0: single packet;1: two packets
        panel-dsi-vbp = <8>; //V back porch lines
        panel-dsi-vfp = <8>; //V front porch lines
        panel-dsi-vsa = <4>;
        //0:blanking packets send during BLLP;1:LP mode used for BLLP
        panel-dsi-bllp-mode = <1>;
        panel-dsi-use-null-pkt-bllp = <0>; //0:blanking packet; 1:Null packet
        panel-dsi-vc = <0x00>; //Virtual channel
        panel-dsi-cmd-type = <0x0>; //0:send in LP mode, 1:send in HS mode
        panel-dsi-clk = <400>;
        //add special config list here
        panel-init-list =  //delay, type, data, parameters, end symbol

                          < 0x00 0x15 0xE0 0x00 0xFFF
			    //       PASSWORD
                            0x00 0x15 0xE1 0x93 0xFFF
                            0x00 0x15 0xE2 0x65 0xFFF
                            0x00 0x15 0xE3 0xF8 0xFFF
                            0x00 0x15 0x80 0x03 0xFFF
			    //    Page 1
                            0x00 0x15 0xE0 0x01 0xFFF
			    // Set VCOM
                            0x00 0x15 0x00 0x00 0xFFF
                            0x00 0x15 0x01 0x32 0xFFF
                            0x00 0x15 0x0C 0x74 0xFFF
			    // Set Gamma Power
                            0x00 0x15 0x17 0x00 0xFFF
                            0x00 0x15 0x18 0xAF 0xFFF
                            0x00 0x15 0x19 0x01 0xFFF
                            0x00 0x15 0x1A 0x00 0xFFF
                            0x00 0x15 0x1B 0xAF 0xFFF
                            0x00 0x15 0x1C 0x01 0xFFF
                            0x00 0x15 0x24 0xFE 0xFFF
			    // Set PANEL
                            0x00 0x15 0x35 0x28 0xFFF
                            0x00 0x15 0x37 0x09 0xFFF
                            0x00 0x15 0x38 0x04 0xFFF
                            0x00 0x15 0x39 0x00 0xFFF
                            0x00 0x15 0x3A 0x01 0xFFF
                            0x00 0x15 0x3C 0x76 0xFFF
                            0x00 0x15 0x3D 0xFF 0xFFF
                            0x00 0x15 0x3E 0xFF 0xFFF
                            0x00 0x15 0x3F 0x7F 0xFFF
			    //   Set TCON
                            0x00 0x15 0x40 0x06 0xFFF
                            0x00 0x15 0x41 0xA0 0xFFF
                            0x00 0x15 0x42 0x81 0xFFF
                            0x00 0x15 0x43 0x08 0xFFF
                            0x00 0x15 0x44 0x0B 0xFFF
			    0x00 0x15 0x45 0x28 0xFFF

                            //0x00 0x15 0x4A 0x30 0xFFF//BIST
			    //    Power  Voltage
                            0x00 0x15 0x55 0x01 0xFFF
                            0x00 0x15 0x57 0x69 0xFFF
                            0x00 0x15 0x59 0x0A 0xFFF
                            0x00 0x15 0x5A 0x28 0xFFF
                            0x00 0x15 0x5B 0x14 0xFFF
			    //      Gamma
                            0x00 0x15 0x5D 0x7C 0xFFF
                            0x00 0x15 0x5E 0x65 0xFFF
                            0x00 0x15 0x5F 0x54 0xFFF
                            0x00 0x15 0x60 0x48 0xFFF
                            0x00 0x15 0x61 0x43 0xFFF
                            0x00 0x15 0x62 0x34 0xFFF
                            0x00 0x15 0x63 0x38 0xFFF
                            0x00 0x15 0x64 0x21 0xFFF
                            0x00 0x15 0x65 0x39 0xFFF
                            0x00 0x15 0x66 0x37 0xFFF
                            0x00 0x15 0x67 0x37 0xFFF
                            0x00 0x15 0x68 0x54 0xFFF
                            0x00 0x15 0x69 0x43 0xFFF
                            0x00 0x15 0x6A 0x49 0xFFF
                            0x00 0x15 0x6B 0x3B 0xFFF
                            0x00 0x15 0x6C 0x36 0xFFF
                            0x00 0x15 0x6D 0x28 0xFFF
                            0x00 0x15 0x6E 0x14 0xFFF
                            0x00 0x15 0x6F 0x00 0xFFF
                            0x00 0x15 0x70 0x7c 0xFFF
                            0x00 0x15 0x71 0x65 0xFFF
                            0x00 0x15 0x72 0x54 0xFFF
                            0x00 0x15 0x73 0x48 0xFFF
                            0x00 0x15 0x74 0x43 0xFFF
                            0x00 0x15 0x75 0x34 0xFFF
                            0x00 0x15 0x76 0x38 0xFFF
                            0x00 0x15 0x77 0x21 0xFFF
                            0x00 0x15 0x78 0x39 0xFFF
                            0x00 0x15 0x79 0x37 0xFFF
                            0x00 0x15 0x7A 0x37 0xFFF
                            0x00 0x15 0x7B 0x54 0xFFF
                            0x00 0x15 0x7C 0x43 0xFFF
                            0x00 0x15 0x7D 0x49 0xFFF
                            0x00 0x15 0x7E 0x3B 0xFFF
                            0x00 0x15 0x7F 0x36 0xFFF
                            0x00 0x15 0x80 0x28 0xFFF
                            0x00 0x15 0x81 0x14 0xFFF
                            0x00 0x15 0x82 0x00 0xFFF
			    //Page2 for GIP
                            0x00 0x15 0xE0 0x02 0xFFF
                            0x00 0x15 0x00 0x1E 0xFFF
                            0x00 0x15 0x01 0x1E 0xFFF
                            0x00 0x15 0x02 0x41 0xFFF
                            0x00 0x15 0x03 0x41 0xFFF
                            0x00 0x15 0x04 0x43 0xFFF
                            0x00 0x15 0x05 0x43 0xFFF
                            0x00 0x15 0x06 0x1F 0xFFF
                            0x00 0x15 0x07 0x1F 0xFFF
                            0x00 0x15 0x08 0x1F 0xFFF
                            0x00 0x15 0x09 0x1F 0xFFF
                            0x00 0x15 0x0A 0x1E 0xFFF
                            0x00 0x15 0x0B 0x1E 0xFFF
                            0x00 0x15 0x0C 0x1F 0xFFF
                            0x00 0x15 0x0D 0x47 0xFFF
                            0x00 0x15 0x0E 0x47 0xFFF
                            0x00 0x15 0x0F 0x45 0xFFF
                            0x00 0x15 0x10 0x45 0xFFF
                            0x00 0x15 0x11 0x4B 0xFFF
                            0x00 0x15 0x12 0x4B 0xFFF
                            0x00 0x15 0x13 0x49 0xFFF
                            0x00 0x15 0x14 0x49 0xFFF
                            0x00 0x15 0x15 0x1F 0xFFF
			    //CIP_R Pin mapping
                            0x00 0x15 0x16 0x1E 0xFFF
                            0x00 0x15 0x17 0x1E 0xFFF
                            0x00 0x15 0x18 0x40 0xFFF
                            0x00 0x15 0x19 0x40 0xFFF
                            0x00 0x15 0x1A 0x42 0xFFF
                            0x00 0x15 0x1B 0x42 0xFFF
                            0x00 0x15 0x1C 0x1F 0xFFF
                            0x00 0x15 0x1D 0x1F 0xFFF
			    0x00 0x15 0x1E 0x1F 0xFFF
                            0x00 0x15 0x1F 0x1F 0xFFF
                            0x00 0x15 0x20 0x1E 0xFFF
                            0x00 0x15 0x21 0x1E 0xFFF
                            0x00 0x15 0x22 0x1F 0xFFF
                            0x00 0x15 0x23 0x46 0xFFF
                            0x00 0x15 0x24 0x46 0xFFF
                            0x00 0x15 0x25 0x44 0xFFF
                            0x00 0x15 0x26 0x44 0xFFF
                            0x00 0x15 0x27 0x4A 0xFFF
                            0x00 0x15 0x28 0x4A 0xFFF
                            0x00 0x15 0x29 0x48 0xFFF
                            0x00 0x15 0x2A 0x48 0xFFF
                            0x00 0x15 0x2B 0x1F 0xFFF
			    //GIP Timing
                            0x00 0x15 0x58 0x40 0xFFF
                            0x00 0x15 0x5B 0x30 0xFFF
                            0x00 0x15 0x5C 0x03 0xFFF
                            0x00 0x15 0x5D 0x30 0xFFF
                            0x00 0x15 0x5E 0x01 0xFFF
                            0x00 0x15 0x5F 0x02 0xFFF
                            0x00 0x15 0x63 0x14 0xFFF
                            0x00 0x15 0x64 0x6A 0xFFF
                            0x00 0x15 0x67 0x73 0xFFF
                            0x00 0x15 0x68 0x05 0xFFF
                            0x00 0x15 0x69 0x14 0xFFF
                            0x00 0x15 0x6A 0x6A 0xFFF
                            0x00 0x15 0x6B 0x08 0xFFF
                            0x00 0x15 0x6C 0x00 0xFFF
                            0x00 0x15 0x6D 0x01 0xFFF
                            0x00 0x15 0x6E 0x01 0xFFF
                            0x00 0x15 0x6F 0x88 0xFFF
                            0x00 0x15 0x77 0xDD 0xFFF
                            0x00 0x15 0x79 0x0E 0xFFF
                            0x00 0x15 0x7A 0x03 0xFFF
                            0x00 0x15 0x7D 0x14 0xFFF
                            0x00 0x15 0x7E 0x6A 0xFFF
			    //Page4
                            0x00 0x15 0xE0 0x04 0xFFF
                            0x00 0x15 0x02 0x23 0xFFF
                            0x00 0x15 0x09 0x10 0xFFF
                            0x00 0x15 0x0E 0x4A 0xFFF
                            0x00 0x15 0x36 0x49 0xFFF

			    0x00 0x15 0xE0 0x00 0xFFF
			    0x00 0x15 0x11 0x00 0xFFF
			    0x78 0x15 0x29 0x00 0xFFF
			    0x0A 0x15 0x35 0x00 0xFFF>;

        status = "disable";
    };
*/
/*
    // 2020_05_22, zzp
    adi04005hm40_ili9806E:lcd-panel@8 { // for MIPI 2lane
        compatible = "adi,adi04005hm40_ili9806E";
        panel-if = <1>; //0 for RGB, 1 for MIPI, 2 for MPU
        panel-rgb-seq = <1>; //0 for BGR, 1 for RGB
        panel-width = <480>;
        panel-height = <800>;
        panel-pclk-div = <19>; //pixel clock = Peri_pll/(pclk_div+1)
        panel-dsi-num-lane = <1>; //0-3: 1lane-4lane
        //0-3: data0-data3, 4: clk
        panel-dsi-txd0 = <0>;
        panel-dsi-txd1 = <1>;
        panel-dsi-txd2 = <4>;
        panel-dsi-txd3 = <2>;
        panel-dsi-txd4 = <3>;

        panel-dsi-noncontinuous-clk = <0>; //0:continuous,1:noncontinuous
        panel-dsi-t-pre = <1>; //t-pre, >=1
        panel-dsi-t-post = <1>; //t-post=tlpx+t-prepare+t-zero+t-pre, >=1
        panel-dsi-tx-gap = <1>; //ths-exit
        panel-dsi-autoinsert-eotp = <0>; //0:not insert,1:auto-insert
        panel-dsi-htx-to-count = <0xFFFFFF>; //high speed TX timeout count
        panel-dsi-lrx-to-count = <0xFFFFFF>; //Low power RX timeout count
        panel-dsi-bta-to-count = <0xFFFFFF>; //Bus turn around timeout count
        panel-dsi-t-wakeup = <0xc8>; //DPHY T-wakeup time
        panel-dsi-pix-fifo-send-level = <64>; //buffer send level <= 512
        //0-2:16-bit config 1-3; 3-4:18-bit config 1-2; 5:24-bit
        panel-dsi-if-color-coding = <0x05>;
        //0:16-bit;1:18-bit;2:18-bit loosely packed;3:24-bit
        panel-dsi-pix-format = <0x03>;
        panel-dsi-vsync-pol = <1>; //0:active low; 1:active high
        panel-dsi-hsync-pol = <1>; //0:active low; 1:active high
        //0:Non-burst mode with sync pulses;
        //1:Noe-burst mode with sync events;
        //2:Burst mode; 3:reserved
        panel-dsi-video-mode = <2>;
        panel-dsi-hfp = <50>; //H front porch blanking packet payload size in bytes
        panel-dsi-hbp = <50>; //H back porch blanking packet payload size in bytes
        panel-dsi-hsa = <10>; //H sync width blanking packet payload size in bytes
        panel-dsi-mult-pkts-en = <0>; //0: single packet;1: two packets
        panel-dsi-vbp = <22>; //V back porch lines
        panel-dsi-vfp = <16>; //V front porch lines
        panel-dsi-vsa = <6>;
        //0:blanking packets send during BLLP;1:LP mode used for BLLP
        panel-dsi-bllp-mode = <1>;
        panel-dsi-use-null-pkt-bllp = <0>; //0:blanking packet; 1:Null packet
        panel-dsi-vc = <0x00>; //Virtual channel
        panel-dsi-cmd-type = <0x0>; //0:send in LP mode, 1:send in HS mode
        panel-dsi-clk = <500>;

        panel-init-list =  //delay, type, data, parameters, end symbol
				<// change to Page1
        0x00 0x39 0xFF 0xFF 0x98 0x06 0x04 0x01 0xFFF

        0x00 0x15 0x08 0x10 0xFFF // output SDA
        0x00 0x15 0x21 0x01  0xFFF // DE=1 Active

        0x00 0x15 0x30 0x02  0xFFF // 480 x 800
        0x00 0x15 0x31 0x02  0xFFF // Column lnversion
        0x00 0x15 0x40 0x10  0xFFF // 2.5VCI/-2VCL 15
        0x00 0x15 0x41 0x33  0xFFF // 6/-6 44 55

        0x00 0x15 0x42 0x03  0xFFF // DDVDH+VCI-VCL/DDVDL-DDVDH

        0x00 0x15 0x43 0x09  0xFFF //VGH_CLAMP OFF
        0x00 0x15 0x44 0x07  0xFFF //VGH_CLAMP ON

        0x00 0x15 0x50 0x78  0xFFF // 50
        0x00 0x15 0x51 0x78  0xFFF // 50

        0x00 0x15 0x52 0x00  0xFFF // Flicker
        0x00 0x15 0x53 0x73  0xFFF // Flicker6D
        0x00 0x15 0x57 0x50  0xFFF // Flicker6D

        0x00 0x15 0x60 0x07  0xFFF // SDTI
        0x00 0x15 0x61 0x00  0xFFF // CRTI
        0x00 0x15 0x62 0x08  0xFFF // EQTI
        0x00 0x15 0x63 0x00  0xFFF // PCTI

        // change to Page1
        0x00 0x39 0xFF 0xFF 0x98 0x06 0x04 0x01 0xFFF
		//  Gamma Setting
        0x00 0x15 0xA0 0x00  0xFFF //Gamma 255
        0x00 0x15 0xA1 0x07  0xFFF //Gamma 251
        0x00 0x15 0xA2 0x0D  0xFFF //Gamma 247
        0x00 0x15 0xA3 0x0C  0xFFF //Gamma 239
        0x00 0x15 0xA4 0x04  0xFFF //Gamma 231
        0x00 0x15 0xA5 0x07  0xFFF //Gamma 203
        0x00 0x15 0xA6 0x06  0xFFF //Gamma 175
        0x00 0x15 0xA7 0x04  0xFFF //Gamma 147
        0x00 0x15 0xA8 0x09  0xFFF //Gamma 108
        0x00 0x15 0xA9 0x0C  0xFFF //Gamma 80
        0x00 0x15 0xAA 0x14  0xFFF //Gamma 52
        0x00 0x15 0xAB 0x08  0xFFF //Gamma 24
        0x00 0x15 0xAC 0x0E  0xFFF //Gamma 16
        0x00 0x15 0xAD 0x17  0xFFF //Gamma 8
        0x00 0x15 0xAE 0x0E  0xFFF //Gamma 4
        0x00 0x15 0xAF 0x00  0xFFF //Gamma 0

        // Nagitive
        0x00 0x15 0xC0 0x00  0xFFF //Gamma 255
        0x00 0x15 0xC1 0x06  0xFFF //Gamma 251
        0x00 0x15 0xC2 0x0C  0xFFF //Gamma 247
        0x00 0x15 0xC3 0x0C  0xFFF //Gamma 239
        0x00 0x15 0xC4 0x04  0xFFF //Gamma 231
        0x00 0x15 0xC5 0x07  0xFFF //Gamma 203
        0x00 0x15 0xC6 0x06  0xFFF //Gamma 175
        0x00 0x15 0xC7 0x04  0xFFF //Gamma 147
        0x00 0x15 0xC8 0x08  0xFFF //Gamma 108
        0x00 0x15 0xC9 0x0C  0xFFF //Gamma 80
        0x00 0x15 0xCA 0x13  0xFFF //Gamma 52
        0x00 0x15 0xCB 0x08  0xFFF //Gamma 24
        0x00 0x15 0xCC 0x0E  0xFFF //Gamma 16
        0x00 0x15 0xCD 0x18  0xFFF //Gamma 8
        0x00 0x15 0xCE 0x0E  0xFFF //Gamma 4
        0x00 0x15 0xCF 0x00  0xFFF //Gamma 0

        // change to Page6
        0x00 0x39 0xFF 0xFF 0x98 0x06 0x04 0x06 0xFFF

        0x00 0x15 0x00 0x21  0xFFF
        0x00 0x15 0x01 0x0A  0xFFF
        0x00 0x15 0x02 0x00  0xFFF
        0x00 0x15 0x03 0x00  0xFFF
        0x00 0x15 0x04 0x01  0xFFF
        0x00 0x15 0x05 0x01  0xFFF
        0x00 0x15 0x06 0x80  0xFFF
        0x00 0x15 0x07 0x06  0xFFF
        0x00 0x15 0x08 0x01  0xFFF
        0x00 0x15 0x09 0x80  0xFFF
        0x00 0x15 0x0A 0x00  0xFFF
        0x00 0x15 0x0B 0x00  0xFFF
        0x00 0x15 0x0C 0x0A  0xFFF
        0x00 0x15 0x0D 0x0A  0xFFF
        0x00 0x15 0x0E 0x00  0xFFF
        0x00 0x15 0x0F 0x00  0xFFF

        0x00 0x15 0x10 0xF0  0xFFF
        0x00 0x15 0x11 0xF4  0xFFF
        0x00 0x15 0x12 0x04  0xFFF
        0x00 0x15 0x13 0x00  0xFFF
        0x00 0x15 0x14 0x00  0xFFF
        0x00 0x15 0x15 0xC0  0xFFF
        0x00 0x15 0x16 0x08  0xFFF
        0x00 0x15 0x17 0x00  0xFFF
        0x00 0x15 0x17 0x00  0xFFF         
        0x00 0x15 0x19 0x00  0xFFF
        0x00 0x15 0x1A 0x00  0xFFF
        0x00 0x15 0x1B 0x00  0xFFF
        0x00 0x15 0x1C 0x00  0xFFF  
        0x00 0x15 0x1D 0x00  0xFFF

        0x00 0x15 0x20 0x01  0xFFF          
        0x00 0x15 0x21 0x23  0xFFF
        0x00 0x15 0x22 0x45  0xFFF
        0x00 0x15 0x23 0x67  0xFFF
        0x00 0x15 0x24 0x01  0xFFF   
        0x00 0x15 0x25 0x23  0xFFF
        0x00 0x15 0x26 0x45  0xFFF
        0x00 0x15 0x27 0x67  0xFFF

        0x00 0x15 0x30 0x01  0xFFF
        0x00 0x15 0x31 0x11  0xFFF   //GOUT1
        0x00 0x15 0x32 0x00  0xFFF   //GOUT2
        0x00 0x15 0x33 0xEE  0xFFF   //GOUT3
        0x00 0x15 0x34 0xFF  0xFFF   //GOUT4
        0x00 0x15 0x35 0xCB  0xFFF   //GOUT5  GCK4
        0x00 0x15 0x36 0xDA  0xFFF   //GOUT6  GCK3
        0x00 0x15 0x37 0xAD  0xFFF   //GOUT7  GCK2
        0x00 0x15 0x38 0xBC  0xFFF   //GOUT8  GCK1
        0x00 0x15 0x39 0x76  0xFFF   //GOUT9 STV1
        0x00 0x15 0x3A 0x67  0xFFF   //GOUT10 STV2
        0x00 0x15 0x3B 0x22  0xFFF   //GOUT11
        0x00 0x15 0x3C 0x22  0xFFF   //GOUT12
        0x00 0x15 0x3D 0x22  0xFFF   //GOUT13
        0x00 0x15 0x3E 0x22  0xFFF   //GOUT14
        0x00 0x15 0x3F 0x22  0xFFF   //

        0x00 0x15 0x40 0x22  0xFFF   //

        0x00 0x15 0x52 0x10  0xFFF   //
        0x00 0x15 0x53 0x10  0xFFF   //
        0x00 0x15 0x54 0x13  0xFFF   //

        //   change to Page7
        0x00 0x39 0xFF 0xFF 0x98 0x06 0x04 0x07 0xFFF

        0x00 0x15 0xB3 0x10  0xFFF
        0x00 0x15 0x17 0x22  0xFFF //VGL_REG ON
        0x00 0x15 0x02 0x77  0xFFF

        0x00 0x15 0x26 0xB2  0xFFF //VCL=-2VCI -3.4V
        0x00 0x15 0xE1 0x79  0xFFF

        //change to Page0
        0x00 0x39 0xFF 0xFF 0x98 0x06 0x04 0x00 0xFFF

        0x00 0x15 0x35 0x00  0xFFF

				0x78 0x05 0x11 0x00 0xFFF//Sleep -OUT
         // Display ON
        0x0 0x05 0x29 0x00 0xFFF>;

        status = "disable";
    };
*/
/*    // 2020_06_01, zzp
    sat101at40128r1_jd9365:lcd-panel@9 { // for MIPI 4lane
        compatible = "sat,sat101at40128r1_jd9365";
        panel-if = <1>; //0 for RGB, 1 for MIPI, 2 for MPU
        panel-rgb-seq = <1>; //0 for BGR, 1 for RGB
        panel-width = <800>;
        panel-height = <1280>;
        panel-pclk-div = <8>; //pixel clock = Peri_pll/(pclk_div+1)
        panel-dsi-num-lane = <3>; //0-3: 1lane-4lane
        //0-3: data0-data3, 4: clk
        panel-dsi-txd0 = <0>;
        panel-dsi-txd1 = <1>;
        panel-dsi-txd2 = <4>;
        panel-dsi-txd3 = <2>;
        panel-dsi-txd4 = <3>;

        panel-dsi-noncontinuous-clk = <1>; //0:continuous,1:noncontinuous
        panel-dsi-t-pre = <1>; //t-pre, >=1
        panel-dsi-t-post = <1>; //t-post=tlpx+t-prepare+t-zero+t-pre, >=1
        panel-dsi-tx-gap = <1>; //ths-exit
        panel-dsi-autoinsert-eotp = <0>; //0:not insert,1:auto-insert
        panel-dsi-htx-to-count = <0xFFFFFF>; //high speed TX timeout count
        panel-dsi-lrx-to-count = <0xFFFFFF>; //Low power RX timeout count
        panel-dsi-bta-to-count = <0xFFFFFF>; //Bus turn around timeout count
        panel-dsi-t-wakeup = <0xc8>; //DPHY T-wakeup time
        panel-dsi-pix-fifo-send-level = <512>; //buffer send level <= 512
        //0-2:16-bit config 1-3; 3-4:18-bit config 1-2; 5:24-bit
        panel-dsi-if-color-coding = <0x05>;
        //0:16-bit;1:18-bit;2:18-bit loosely packed;3:24-bit
        panel-dsi-pix-format = <0x03>;
        panel-dsi-vsync-pol = <0>; //0:active low; 1:active high
        panel-dsi-hsync-pol = <0>; //0:active low; 1:active high
        //0:Non-burst mode with sync pulses;
        //1:Noe-burst mode with sync events;
        //2:Burst mode; 3:reserved
        panel-dsi-video-mode = <2>;
        panel-dsi-hfp = <20>; //H front porch blanking packet payload size in bytes
        panel-dsi-hbp = <20>; //H back porch blanking packet payload size in bytes
        panel-dsi-hsa = <20>; //H sync width blanking packet payload size in bytes
        panel-dsi-mult-pkts-en = <0>; //0: single packet;1: two packets
        panel-dsi-vbp = <8>; //V back porch lines
        panel-dsi-vfp = <30>; //V front porch lines
        panel-dsi-vsa = <4>;
        //0:blanking packets send during BLLP;1:LP mode used for BLLP
        panel-dsi-bllp-mode = <1>;
        panel-dsi-use-null-pkt-bllp = <0>; //0:blanking packet; 1:Null packet
        panel-dsi-vc = <0x00>; //Virtual channel
        panel-dsi-cmd-type = <0x0>; //0:send in LP mode, 1:send in HS mode
        panel-dsi-clk = <600>;

        // delay, type, data, parameters, end symbol
        panel-init-list = < // page0
                            0x00 0x23 0xE0 0x00 0xFFF
                            // password
                            0x00 0x23 0xE1 0x93 0xFFF
                            0x00 0x23 0xE2 0x65 0xFFF
                            0x00 0x23 0xE3 0xF8 0xFFF
                            0x00 0x23 0x80 0x03 0xFFF
							// page1
                            0x00 0x23 0xE0 0x01 0xFFF
                            // set VCOM
                            0x00 0x23 0x00 0x00 0xFFF
                            0x00 0x23 0x01 0x26 0xFFF

                            // Set Gamma Power, VGMP,VGMN,VGSP,VGSN
                            0x00 0x23 0x17 0x00 0xFFF
                            0x00 0x23 0x18 0xD7 0xFFF
                            0x00 0x23 0x19 0x01 0xFFF
                            0x00 0x23 0x1A 0x00 0xFFF
                            0x00 0x23 0x1B 0xD7 0xFFF
                            0x00 0x23 0x1C 0x01 0xFFF

                            0x00 0x23 0x1F 0x70 0xFFF
                            0x00 0x23 0x20 0x2D 0xFFF
                            0x00 0x23 0x21 0x2D 0xFFF
                            0x00 0x23 0x22 0x7E 0xFFF

                            0x00 0x23 0x24 0xFD 0xFFF

                            0x00 0x23 0x37 0x19 0xFFF

                            0x00 0x23 0x35 0x28 0xFFF
                            // Set RGBCYC
                            0x00 0x23 0x38 0x05 0xFFF
                            0x00 0x23 0x39 0x08 0xFFF
                            0x00 0x23 0x3A 0x12 0xFFF
                            0x00 0x23 0x3C 0x7E 0xFFF
                            0x00 0x23 0x3D 0xFF 0xFFF
                            0x00 0x23 0x3E 0xFF 0xFFF
                            0x00 0x23 0x3F 0x7F 0xFFF
                            //  Set TCON
                            0x00 0x23 0x40 0x06 0xFFF  // RSO
                            0x00 0x23 0x41 0xA0 0xFFF  // LN=640->1280 line
                            0x00 0x23 0x43 0x1E 0xFFF  // VFP=30
                            0x00 0x23 0x44 0x0B 0xFFF  // VBP=12

                            //  Power Voltage
                            0x00 0x23 0x55 0x01 0xFFF  // DCDCM=1111
                            0x00 0x23 0x56 0x01 0xFFF
                            0x00 0x23 0x57 0x6A 0xFFF
                            0x00 0x23 0x58 0x09 0xFFF
                            0x00 0x23 0x59 0x0A 0xFFF  // VCL = -2.5V
                            0x00 0x23 0x5A 0x2E 0xFFF  // VGH =16V
                            0x00 0x23 0x5B 0x1A 0xFFF  // VGL = -12V
                            0x00 0x23 0x5C 0x15 0xFFF  // PUMP CLK
                            //  Gamma
                            0x00 0x23 0x5D 0x7F 0xFFF
                            0x00 0x23 0x5E 0x5D 0xFFF
                            0x00 0x23 0x5F 0x4B 0xFFF
                            0x00 0x23 0x60 0x3E 0xFFF
                            0x00 0x23 0x61 0x3A 0xFFF
                            0x00 0x23 0x62 0x2B 0xFFF
                            0x00 0x23 0x63 0x2F 0xFFF
                            0x00 0x23 0x64 0x19 0xFFF
                            0x00 0x23 0x65 0x32 0xFFF
                            0x00 0x23 0x66 0x31 0xFFF
                            0x00 0x23 0x67 0x31 0xFFF
                            0x00 0x23 0x68 0x4F 0xFFF
                            0x00 0x23 0x69 0x3E 0xFFF
                            0x00 0x23 0x6A 0x47 0xFFF
                            0x00 0x23 0x6B 0x36 0xFFF
                            0x00 0x23 0x6C 0x31 0xFFF
                            0x00 0x23 0x6D 0x24 0xFFF
                            0x00 0x23 0x6E 0x12 0xFFF
                            0x00 0x23 0x6F 0x02 0xFFF
                            0x00 0x23 0x70 0x7F 0xFFF
                            0x00 0x23 0x71 0x5D 0xFFF
                            0x00 0x23 0x72 0x4B 0xFFF
                            0x00 0x23 0x73 0x3E 0xFFF
                            0x00 0x23 0x74 0x3A 0xFFF
                            0x00 0x23 0x75 0x2B 0xFFF
                            0x00 0x23 0x76 0x2F 0xFFF
                            0x00 0x23 0x77 0x19 0xFFF
                            0x00 0x23 0x78 0x32 0xFFF
                            0x00 0x23 0x79 0x31 0xFFF
                            0x00 0x23 0x7A 0x31 0xFFF
                            0x00 0x23 0x7B 0x4F 0xFFF
                            0x00 0x23 0x7C 0x3E 0xFFF
                            0x00 0x23 0x7D 0x47 0xFFF
                            0x00 0x23 0x7E 0x36 0xFFF
                            0x00 0x23 0x7F 0x31 0xFFF
                            0x00 0x23 0x80 0x24 0xFFF
                            0x00 0x23 0x81 0x12 0xFFF
                            0x00 0x23 0x82 0x02 0xFFF
                            // page2
                            0x00 0x23 0xE0 0x02 0xFFF
                            // GIP_L PIN mapping
                            0x00 0x23 0x00 0x50 0xFFF
                            0x00 0x23 0x01 0x55 0xFFF
                            0x00 0x23 0x02 0x55 0xFFF
                            0x00 0x23 0x03 0x50 0xFFF
                            0x00 0x23 0x04 0x77 0xFFF
                            0x00 0x23 0x05 0x57 0xFFF
                            0x00 0x23 0x06 0x55 0xFFF
                            0x00 0x23 0x07 0x4E 0xFFF
                            0x00 0x23 0x08 0x4C 0xFFF
                            0x00 0x23 0x09 0x5F 0xFFF
                            0x00 0x23 0x0A 0x4A 0xFFF
                            0x00 0x23 0x0B 0x48 0xFFF
                            0x00 0x23 0x0C 0x55 0xFFF
                            0x00 0x23 0x0D 0x46 0xFFF
                            0x00 0x23 0x0E 0x44 0xFFF
                            0x00 0x23 0x0F 0x40 0xFFF
                            0x00 0x23 0x10 0x55 0xFFF
                            0x00 0x23 0x11 0x55 0xFFF
                            0x00 0x23 0x12 0x55 0xFFF
                            0x00 0x23 0x13 0x55 0xFFF
                            0x00 0x23 0x14 0x55 0xFFF
                            0x00 0x23 0x15 0x55 0xFFF
                            // GIP_R PIN mapping
                            0x00 0x23 0x16 0x53 0xFFF
                            0x00 0x23 0x17 0x55 0xFFF
                            0x00 0x23 0x18 0x55 0xFFF
                            0x00 0x23 0x19 0x51 0xFFF
                            0x00 0x23 0x1A 0x77 0xFFF
                            0x00 0x23 0x1B 0x57 0xFFF
                            0x00 0x23 0x1C 0x55 0xFFF
                            0x00 0x23 0x1D 0x4F 0xFFF
                            0x00 0x23 0x1E 0x4D 0xFFF
                            0x00 0x23 0x1F 0x5F 0xFFF
                            0x00 0x23 0x20 0x4B 0xFFF
                            0x00 0x23 0x21 0x49 0xFFF
                            0x00 0x23 0x22 0x55 0xFFF
                            0x00 0x23 0x23 0x47 0xFFF
                            0x00 0x23 0x24 0x45 0xFFF
                            0x00 0x23 0x25 0x41 0xFFF
                            0x00 0x23 0x26 0x55 0xFFF
                            0x00 0x23 0x27 0x55 0xFFF
                            0x00 0x23 0x28 0x55 0xFFF
                            0x00 0x23 0x29 0x55 0xFFF
                            0x00 0x23 0x2A 0x55 0xFFF
                            0x00 0x23 0x2B 0x55 0xFFF
                            //  GIP_L_GS PIN mapping
                            0x00 0x23 0x2C 0x13 0xFFF
                            0x00 0x23 0x2D 0x15 0xFFF
                            0x00 0x23 0x2E 0x15 0xFFF
                            0x00 0x23 0x2F 0x01 0xFFF
                            0x00 0x23 0x30 0x37 0xFFF
                            0x00 0x23 0x31 0x17 0xFFF
                            0x00 0x23 0x32 0x15 0xFFF
                            0x00 0x23 0x33 0x0D 0xFFF
                            0x00 0x23 0x34 0x0F 0xFFF
                            0x00 0x23 0x35 0x15 0xFFF
                            0x00 0x23 0x36 0x05 0xFFF
                            0x00 0x23 0x37 0x07 0xFFF
                            0x00 0x23 0x38 0x15 0xFFF
                            0x00 0x23 0x39 0x09 0xFFF
                            0x00 0x23 0x3A 0x0B 0xFFF
                            0x00 0x23 0x3B 0x11 0xFFF
                            0x00 0x23 0x3C 0x15 0xFFF
                            0x00 0x23 0x3D 0x15 0xFFF
                            0x00 0x23 0x3E 0x15 0xFFF
                            0x00 0x23 0x3F 0x15 0xFFF
                            0x00 0x23 0x40 0x15 0xFFF
                            0x00 0x23 0x41 0x15 0xFFF

                            //  GIP_R_GS PIN mapping
                            0x00 0x23 0x42 0x12 0xFFF
                            0x00 0x23 0x43 0x15 0xFFF
                            0x00 0x23 0x44 0x15 0xFFF
                            0x00 0x23 0x45 0x00 0xFFF
                            0x00 0x23 0x46 0x37 0xFFF
                            0x00 0x23 0x47 0x17 0xFFF
                            0x00 0x23 0x48 0x15 0xFFF
                            0x00 0x23 0x49 0x0C 0xFFF
                            0x00 0x23 0x4A 0x0E 0xFFF
                            0x00 0x23 0x4B 0x15 0xFFF
                            0x00 0x23 0x4C 0x04 0xFFF
                            0x00 0x23 0x4D 0x06 0xFFF
                            0x00 0x23 0x4E 0x15 0xFFF
                            0x00 0x23 0x4F 0x08 0xFFF
                            0x00 0x23 0x50 0x0A 0xFFF
                            0x00 0x23 0x51 0x10 0xFFF
                            0x00 0x23 0x52 0x15 0xFFF
                            0x00 0x23 0x53 0x15 0xFFF
                            0x00 0x23 0x54 0x15 0xFFF
                            0x00 0x23 0x55 0x15 0xFFF
                            0x00 0x23 0x56 0x15 0xFFF
                            0x00 0x23 0x57 0x15 0xFFF
                            // GIP Timing
                            0x00 0x23 0x58 0x40 0xFFF

                            0x00 0x23 0x5B 0x10 0xFFF
                            0x00 0x23 0x5C 0x06 0xFFF
                            0x00 0x23 0x5D 0x40 0xFFF
                            0x00 0x23 0x5E 0x00 0xFFF
                            0x00 0x23 0x5F 0x00 0xFFF
                            0x00 0x23 0x60 0x40 0xFFF
                            0x00 0x23 0x61 0x03 0xFFF
                            0x00 0x23 0x62 0x04 0xFFF
                            0x00 0x23 0x63 0x6C 0xFFF
                            0x00 0x23 0x64 0x6C 0xFFF
                            0x00 0x23 0x65 0x75 0xFFF
                            0x00 0x23 0x66 0x08 0xFFF
                            0x00 0x23 0x67 0xB4 0xFFF
                            0x00 0x23 0x68 0x08 0xFFF
                            0x00 0x23 0x69 0x6C 0xFFF
                            0x00 0x23 0x6A 0x6C 0xFFF
                            0x00 0x23 0x6B 0x0C 0xFFF

                            0x00 0x23 0x6D 0x00 0xFFF
                            0x00 0x23 0x6E 0x00 0xFFF
                            0x00 0x23 0x6F 0x88 0xFFF

                            0x00 0x23 0x75 0xBB 0xFFF
                            0x00 0x23 0x76 0x00 0xFFF
                            0x00 0x23 0x77 0x05 0xFFF
                            0x00 0x23 0x78 0x2A 0xFFF
                            //  page4
                            0x00 0x23 0xE0 0x04 0xFFF
                            0x78 0x13 0x09 0x11 0xFFF
                            0x05 0x13 0x0E 0x48 0xFFF
                            0x05 0x13 0x2D 0x03 0xFFF

                            //  page0
                            0x00 0x23 0xE0 0x00 0xFFF
                            0x00 0x23 0xE6 0x02 0xFFF
                            0x00 0x23 0xE7 0x06 0xFFF
                            0x78 0x05 0x11 0x00 0xFFF
                            0x05 0x05 0x29 0x00 0xFFF
                            0x00 0x15 0x35 0x00 0xFFF
                            0x00 0x23 0xE0 0x00 0xFFF>;

        status = "disable";
    };
*/
/*
    FRD350C25024: lcd-panel@10{  // for MIPI 1lane
            compatible = "ST7796S,FRD350C25024";
            panel-if = <1>; //0 for RGB, 1 for MIPI, 2 for MPU
            panel-rgb-seq = <1>; //0 for BGR, 1 for RGB
            panel-width = <320>;
            panel-height = <480>;
            panel-pclk-div = <65>; //pixel clock = Peri_pll/(pclk_div+1)
            panel-dsi-num-lane = <0>; //0-3: 1lane-4lane
            //0-3: data0-data3, 4: clk
            panel-dsi-txd0 = <0>;
            panel-dsi-txd2 = <4>;
            panel-dsi-noncontinuous-clk = <0>; //0:continuous,1:noncontinuous
            panel-dsi-t-pre = <1>; //t-pre, >=1
            panel-dsi-t-post = <1>; //t-post=tlpx+t-prepare+t-zero+t-pre, >=1
            panel-dsi-tx-gap = <1>; //ths-exit
            panel-dsi-autoinsert-eotp = <0>; //0:not insert,1:auto-insert
            panel-dsi-htx-to-count = <0xFFFFFF>; //high speed TX timeout count
            panel-dsi-lrx-to-count = <0xFFFFFF>; //Low power RX timeout count
            panel-dsi-bta-to-count = <0xFFFFFF>; //Bus turn around timeout count
            panel-dsi-t-wakeup = <0xc8>; //DPHY T-wakeup time
            panel-dsi-pix-fifo-send-level = <320>; //buffer send level <= 512
            //0-2:16-bit config 1-3; 3-4:18-bit config 1-2; 5:24-bit
            panel-dsi-if-color-coding = <0x05>;
            //0:16-bit;1:18-bit;2:18-bit loosely packed;3:24-bit
            panel-dsi-pix-format = <0x03>;
            panel-dsi-vsync-pol = <0>; //0:active low; 1:active high
            panel-dsi-hsync-pol = <0>; //0:active low; 1:active high
            //0:Non-burst mode with sync pulses;
            //1:Noe-burst mode with sync events;
            //2:Burst mode; 3:reserved
            panel-dsi-video-mode = <2>;
            panel-dsi-hfp = <10>; //H front porch blanking packet payload size in bytes
            panel-dsi-hbp = <30>; //H back porch blanking packet payload size in bytes
            panel-dsi-hsa = <5>; //H sync width blanking packet payload size in bytes
            panel-dsi-mult-pkts-en = <0>; //0: single packet;1: two packets
            panel-dsi-vbp = <30>; //V back porch lines
            panel-dsi-vfp = <30>; //V front porch lines
            panel-dsi-vsa = <5>;
            //0:blanking packets send during BLLP;1:LP mode used for BLLP
            panel-dsi-bllp-mode = <1>;
            panel-dsi-use-null-pkt-bllp = <0>; //0:blanking packet; 1:Null packet
            panel-dsi-vc = <0x00>; //Virtual channel
            panel-dsi-cmd-type = <0x0>; //0:send in LP mode, 1:send in HS mode
            panel-dsi-clk = <300>;

            panel-init-list =  //delay, type, data, parameters, end symbol
                            < 0x78 0x05 0x11 0xFFF
                              0x78 0x15 0x36 0x48 0xFFF
                              0x00 0x15 0x3A 0x77 0xFFF
                              0x00 0x15 0xF0 0xC3 0xFFF
                              0x00 0x15 0xF0 0x96 0xFFF
                              0x00 0x15 0xB4 0x01 0xFFF
                              0x00 0x15 0xB7 0xC6 0xFFF
                              0x00 0x39 0xB9 0x02 0xE0 0xFFF
                              0x00 0x39 0xC0 0x80 0x75 0xFFF
                              0x00 0x15 0xC1 0x13 0xFFF
                              0x00 0x15 0xC2 0xA7 0xFFF
                              0x00 0x15 0xC5 0x1D 0xFFF
                              0x00 0x39 0xE8 0x40 0x8A 0x00 0x00 0x29 0x19 0xA5 0x33 0xFFF
                              0x00 0x39 0xE0 0xD0 0x02 0x0A 0x10 0x11 0x0C 0x35 0x44 0x46 0x3C 0x15 0x13 0x17 0x1A 0xFFF
                              0x00 0x39 0xE1 0xD0 0x01 0x08 0x0B 0x0C 0x17 0x35 0x44 0x47 0x09 0x18 0x17 0x19 0x1D 0xFFF
                              0x00 0x15 0x35 0x00 0xFFF
                              0x00 0x15 0xF0 0x3C 0xFFF
                              0x00 0x15 0xF0 0x69 0xFFF
                              0x78 0x05 0x29 0xFFF>;
        status = "disable";
    };
*/

/*
     FRD400V25030: lcd-panel@11{  // for MIPI 2lane
            compatible = "ST7701,FRD400V25030";
            panel-if = <1>; //0 for RGB, 1 for MIPI, 2 for MPU
            panel-rgb-seq = <1>; //0 for BGR, 1 for RGB

            panel-width = <480>;
            panel-height = <800>;
            panel-pclk-div = <19>; //pixel clock = Peri_pll/(pclk_div+1)
            panel-dsi-num-lane = <1>; //0-3: 1lane-4lane
            //0-3: data0-data3, 4: clk
            panel-dsi-txd0 = <0>;
            panel-dsi-txd1 = <1>;
            panel-dsi-txd2 = <4>;

            panel-dsi-noncontinuous-clk = <0>; //0:continuous,1:noncontinuous
            panel-dsi-t-pre = <1>; //t-pre, >=1
            panel-dsi-t-post = <1>; //t-post=tlpx+t-prepare+t-zero+t-pre, >=1
            panel-dsi-tx-gap = <1>; //ths-exit
            panel-dsi-autoinsert-eotp = <0>; //0:not insert,1:auto-insert
            panel-dsi-htx-to-count = <0xFFFFFF>; //high speed TX timeout count
            panel-dsi-lrx-to-count = <0xFFFFFF>; //Low power RX timeout count
            panel-dsi-bta-to-count = <0xFFFFFF>; //Bus turn around timeout count
            panel-dsi-t-wakeup = <0xc8>; //DPHY T-wakeup time
            panel-dsi-pix-fifo-send-level = <480>; //buffer send level <= 512
            //0-2:16-bit config 1-3; 3-4:18-bit config 1-2; 5:24-bit
            panel-dsi-if-color-coding = <0x05>;
            //0:16-bit;1:18-bit;2:18-bit loosely packed;3:24-bit
            panel-dsi-pix-format = <0x03>;
            panel-dsi-vsync-pol = <0>; //0:active low; 1:active high
            panel-dsi-hsync-pol = <0>; //0:active low; 1:active high
            //0:Non-burst mode with sync pulses;
            //1:Noe-burst mode with sync events;
            //2:Burst mode; 3:reserved
            panel-dsi-video-mode = <2>;
            panel-dsi-hfp = <20>; //H front porch blanking packet payload size in bytes
            panel-dsi-hbp = <20>; //H back porch blanking packet payload size in bytes
            panel-dsi-hsa = <5>; //H sync width blanking packet payload size in bytes
            panel-dsi-mult-pkts-en = <0>; //0: single packet;1: two packets
            panel-dsi-vbp = <25>; //V back porch lines
            panel-dsi-vfp = <35>; //V front porch lines
            panel-dsi-vsa = <1>;
            //0:blanking packets send during BLLP;1:LP mode used for BLLP
            panel-dsi-bllp-mode = <1>;
            panel-dsi-use-null-pkt-bllp = <0>; //0:blanking packet; 1:Null packet
            panel-dsi-vc = <0x00>; //Virtual channel
            panel-dsi-cmd-type = <0x0>; //0:send in LP mode, 1:send in HS mode
            panel-dsi-clk = <500>;

            panel-init-list =  //delay, type, data, parameters, end symbol
                            <
                              0x00 0x39 0xFF 0x77 0x01 0x00 0x00 0x13 0xFFF
                              0x00 0x15 0xEF 0x08 0xFFF
                              0x00 0x39 0xFF 0x77 0x01 0x00 0x00 0x10 0xFFF
                              0x00 0x39 0xC0 0x63 0x00 0xFFF
                              0x00 0x39 0xC1 0x0C 0x0A 0xFFF
                              0x00 0x39 0xC2 0x07 0x0F 0xFFF
                              0x00 0x15 0xCC 0x10 0xFFF
                              0x00 0x39 0xB0 0x08 0x0C 0x16 0x09 0x0D 0x05 0x00 0x08 0x08 0x1C 0x04 0x12 0x10 0x26 0x2D 0x1F 0xFFF
                              0x00 0x39 0xB1 0x0F 0x17 0x18 0x0E 0x10 0x05 0x01 0x08 0x08 0x1D 0x05 0x12 0x10 0x28 0x2F 0x1F 0xFFF
                              0x00 0x39 0xFF 0x77 0x01 0x00 0x00 0x11 0xFFF
                              0x00 0x15 0xB0 0x87 0xFFF
                              0x00 0x15 0xB1 0x53 0xFFF
                              0x00 0x15 0xB2 0x87 0xFFF
                              0x00 0x15 0xB3 0x80 0xFFF
                              0x00 0x15 0xB5 0x47 0xFFF
                              0x00 0x15 0xB7 0x85 0xFFF
                              0x00 0x15 0xB8 0x21 0xFFF
                              0x00 0x15 0xB9 0x10 0xFFF
                              0x00 0x15 0xC1 0x78 0xFFF
                              0x00 0x15 0xC2 0x78 0xFFF
                              0x64 0x15 0xD0 0x88 0xFFF

                              0x00 0x39 0xE0 0x80 0x00 0x02 0xFFF
                              0x00 0x39 0xE1 0x04 0xA0 0x06 0xA0 0x05 0xA0 0x07 0xA0 0x00 0x44 0x44 0xFFF
                              0x00 0x39 0xE2 0x33 0x33 0x44 0x44 0x28 0xA0 0x2A 0xA0 0x29 0xA0 0x2B 0xA0 0x00 0xFFF
                              0x00 0x39 0xE3 0x00 0x00 0x33 0x33 0xFFF
                              0x00 0x39 0xE4 0x44 0x44 0xFFF

                              0x00 0x39 0xE5 0x06 0x2A 0xA0 0xA0 0x08 0x2C 0xA0 0xA0 0x0A 0x2E 0xA0 0xA0 0x0C 0x30 0xA0 0xA0 0xFFF
                              0x00 0x39 0xE6 0x00 0x00 0x33 0x33 0xFFF
                              0x00 0x39 0xE7 0x44 0x44 0xFFF
                              0x00 0x39 0xE8 0x07 0x2B 0xA0 0xA0 0x09 0x2D 0xA0 0xA0 0x0B 0x2F 0xA0 0xA0 0x0D 0x31 0xA0 0xA0 0xFFF
                              0x00 0x39 0xEB 0x00 0x01 0x4E 0x4E 0xEE 0x44 0x00 0xFFF
                              0x00 0x39 0xED 0xFF 0xF1 0x04 0x56 0x72 0x3F 0xFF 0xFF 0xFF 0xFF 0xF3 0x27 0x65 0x40 0x1F 0xFF 0xFFF
                              0x00 0x39 0xEF 0x08 0x08 0x08 0x45 0x3F 0x54 0xFFF
                              0x00 0x39 0xFF 0x77 0x01 0x00 0x00 0x13 0xFFF
                              0x00 0x39 0xE8 0x00 0x0E 0xFFF
                              0x00 0x39 0xFF 0x77 0x01 0x00 0x00 0x00 0xFFF

                              0x78 0x05 0x11 0xFFF
                              0x00 0x39 0xFF 0x77 0x01 0x00 0x00 0x13 0xFFF
                              0x0A 0x39 0xE8 0x00 0x0C 0xFFF
                              0x00 0x39 0xE8 0x00 0x00 0xFFF
                              0x00 0x39 0xFF 0x77 0x01 0x00 0x00 0x00 0xFFF

                              0x00 0x15 0x21 0x00 0xFFF
                              0x14 0x05 0x29 0xFFF
                              0x00 0x15 0x35 0x00 0xFFF
                              >;
        status = "disable";
    };
*/

/*
    lx45fwi4076: lcd-panel@12 { // for MIPI 2lane
        compatible = "ST7701S,lx45fwi4076";
        panel-if = <1>; //0 for RGB, 1 for MIPI, 2 for MPU
        panel-rgb-seq = <1>; //0 for BGR, 1 for RGB
        panel-width = <480>;
        panel-height = <854>;
        panel-pclk-div = <17>; //pixel clock = Peri_pll/(pclk_div+1)
        panel-dsi-num-lane = <1>; //0-3: 1lane-4lane
        //0-3: data0-data3, 4: clk
        panel-dsi-txd0 = <0>;
        panel-dsi-txd1 = <1>;
        panel-dsi-txd2 = <4>;

		// This Driver IC must be working in noncontinous
        panel-dsi-noncontinuous-clk = <1>; //0:continuous,1:noncontinuous
        panel-dsi-t-pre = <1>; //t-pre, >=1
        panel-dsi-t-post = <1>; //t-post=tlpx+t-prepare+t-zero+t-pre, >=1
        panel-dsi-tx-gap = <1>; //ths-exit, >=1
        panel-dsi-autoinsert-eotp = <0>; //0:not insert,1:auto-insert
        panel-dsi-htx-to-count = <0xFFFFFF>; //high speed TX timeout count
        panel-dsi-lrx-to-count = <0xFFFFFF>; //Low power RX timeout count
        panel-dsi-bta-to-count = <0xFFFFFF>; //Bus turn around timeout count
        panel-dsi-t-wakeup = <0xc8>; //DPHY T-wakeup time
        panel-dsi-pix-fifo-send-level = <480>; //buffer send level <= 512
        //0-2:16-bit config 1-3; 3-4:18-bit config 1-2; 5:24-bit
        panel-dsi-if-color-coding = <0x05>;
        //0:16-bit;1:18-bit;2:18-bit loosely packed;3:24-bit
        panel-dsi-pix-format = <0x03>;
        panel-dsi-vsync-pol = <0>; //0:active low; 1:active high
        panel-dsi-hsync-pol = <0>; //0:active low; 1:active high
        //0:Non-burst mode with sync pulses;
        //1:Noe-burst mode with sync events;
        //2:Burst mode; 3:reserved
        panel-dsi-video-mode = <2>;
        panel-dsi-hfp = <50>; //H front porch blanking packet payload size in bytes
        panel-dsi-hbp = <50>; //H back porch blanking packet payload size in bytes
        panel-dsi-hsa = <10>; //H sync width blanking packet payload size in bytes
        panel-dsi-mult-pkts-en = <0>; //0: single packet;1: two packets
        panel-dsi-vbp = <20>; //V back porch lines
        panel-dsi-vfp = <20>; //V front porch lines
        panel-dsi-vsa = <4>;
        //0:blanking packets send during BLLP;1:LP mode used for BLLP
        panel-dsi-bllp-mode = <1>;
        panel-dsi-use-null-pkt-bllp = <0>; //0:blanking packet; 1:Null packet
        panel-dsi-vc = <0x00>; //Virtual channel
        panel-dsi-cmd-type = <0x0>; //0:send in LP mode, 1:send in HS mode
        panel-dsi-clk = <500>;

        panel-init-list = <0x00 0x39 0xFF 0x77 0x01 0x00 0x00 0x10 0xFFF           //delay, type, data, end symbol
                           0x00 0x39 0xC0 0xE9 0x03 0xFFF
                           0x00 0x39 0xC1 0x12 0x02 0xFFF
                           0x00 0x39 0xC2 0x37 0x08 0xFFF
                           0x00 0x15 0xCC 0x10 0xFFF
                           0x00 0x39 0xB0 0x00 0x0A 0x13 0x0E 0x12 0x07 0x05 0x08 0x08 0x1F 0x07 0x15 0X13 0xE3 0x2A 0x11 0xFFF
                           0x00 0x39 0xB1 0x00 0x0A 0x12 0x0E 0x12 0x07 0x04 0x07 0x07 0x1E 0x04 0x13 0x10 0x23 0x29 0x11 0xFFF
                           0x00 0x39 0xFF 0x77 0x01 0x00 0x00 0x11 0xFFF
                           0x00 0x15 0xB0 0x8D 0xFFF
                           0x00 0x15 0xB1 0x1D 0xFFF
                           0x00 0x15 0xB2 0x07 0xFFF
                           0x00 0x15 0xB3 0x80 0xFFF
                           0x00 0x15 0xB5 0x47 0xFFF
                           0x00 0x15 0xB7 0x85 0xFFF
                           0x00 0x15 0xB8 0x21 0xFFF
                           0x00 0x15 0xB9 0x10 0xFFF
                           0x00 0x15 0xC1 0x78 0xFFF
                           0x00 0x15 0xC2 0x78 0xFFF
                           0x64 0x15 0xD0 0x88 0xFFF
                           0x00 0x39 0xE0 0x00 0x00 0x02 0xFFF
                           0x00 0x39 0xE1 0x0B 0x00 0x0D 0x00 0x0C 0x00 0x0E 0x00 0x00 0x44 0x44 0xFFF
                           0x00 0x39 0xE2 0x33 0x33 0x44 0x44 0x64 0x00 0x66 0x00 0x65 0x00 0x67 0x00 0x00 0xFFF
                           0x00 0x39 0xE3 0x00 0x00 0x33 0x33 0xFFF
                           0x00 0x39 0xE4 0x44 0x44 0xFFF
                           0x00 0x39 0xE5 0x0C 0x78 0xA0 0xA0 0x0E 0x78 0xA0 0xA0 0x10 0x78 0xA0 0xA0 0x12 0x78 0xA0 0xA0 0xFFF
                           0x00 0x39 0xE6 0x00 0x00 0x33 0x33 0xFFF
                           0x00 0x39 0xE7 0x44 0x44 0xFFF
                           0x00 0x39 0xE8 0x0D 0x78 0xA0 0xA0 0x0F 0x78 0xA0 0xA0 0x11 0x78 0xA0 0xA0 0x13 0x78 0xA0 0xA0 0xFFF
                           0x00 0x39 0xEB 0x02 0x00 0x39 0x39 0xEE 0x44 0x00 0xFFF
                           0x00 0x39 0xEC 0x00 0x00 0xFFF
                           0x00 0x39 0xED 0xFF 0xF1 0x04 0x56 0x72 0x3F 0xFF 0xFF 0xFF 0xFF 0xF3 0x27 0x65 0x40 0x1F 0xFF 0xFFF
                           0x00 0x39 0xFF 0x77 0x01 0x00 0x00 0x00 0xFFF
                           0x78 0x05 0x11 0xFFF
                           0x78 0x05 0x29 0xFFF>;

        status = "disable";
	};
*/

/*
    ue050hd: lcd-panel@13{ //for MIPI 4 lane
        compatible = "ILI9881D,ue050hd";
        panel-if = <1>; //0 for RGB, 1 for MIPI, 2 for MPU

        panel-rgb-seq = <1>; //0 for BGR, 1 for RGB
        panel-width = <720>;
        panel-height = <1280>;
        panel-pclk-div = <10>; //pixel clock = Peri_pll/(pclk_div+1)
        panel-dsi-num-lane = <3>; //0-3: 1lane-4lane
        //0-3: data0-data3, 4: clk
        panel-dsi-txd0 = <0>;
        panel-dsi-txd1 = <1>;
        panel-dsi-txd2 = <4>;
        panel-dsi-txd3 = <2>;
        panel-dsi-txd4 = <3>;
        panel-dsi-noncontinuous-clk = <0>; //0:continuous,1:noncontinuous
        panel-dsi-t-pre = <1>; //t-pre, >=1
        panel-dsi-t-post = <1>; //t-post=tlpx+t-prepare+t-zero+t-pre, >=1
        panel-dsi-tx-gap = <1>; //ths-exit
        panel-dsi-autoinsert-eotp = <0>; //0:not insert,1:auto-insert
        panel-dsi-htx-to-count = <0xFFFFFF>; //high speed TX timeout count
        panel-dsi-lrx-to-count = <0xFFFFFF>; //Low power RX timeout count
        panel-dsi-bta-to-count = <0xFFFFFF>; //Bus turn around timeout count
        panel-dsi-t-wakeup = <0xc8>; //DPHY T-wakeup time
        panel-dsi-pix-fifo-send-level = <512>; //buffer send level <= 512
        //0-2:16-bit config 1-3; 3-4:18-bit config 1-2; 5:24-bit
        panel-dsi-if-color-coding = <0x05>;
        //0:16-bit;1:18-bit;2:18-bit loosely packed;3:24-bit
        panel-dsi-pix-format = <0x03>;
        panel-dsi-vsync-pol = <0>; //0:active low; 1:active high
        panel-dsi-hsync-pol = <0>; //0:active low; 1:active high
        //0:Non-burst mode with sync pulses;
        //1:Noe-burst mode with sync events;
        //2:Burst mode; 3:reserved
        panel-dsi-video-mode = <2>;
        panel-dsi-hfp = <100>; //H front porch blanking packet payload size in bytes
        panel-dsi-hbp = <20>; //H back porch blanking packet payload size in bytes
        panel-dsi-hsa = <20>; //H sync width blanking packet payload size in bytes
        panel-dsi-mult-pkts-en = <0>; //0: single packet;1: two packets
        panel-dsi-vbp = <15>; //V back porch lines
        panel-dsi-vfp = <15>; //V front porch lines
        panel-dsi-vsa = <2>;
        //0:blanking packets send during BLLP;1:LP mode used for BLLP
        panel-dsi-bllp-mode = <1>;
        panel-dsi-use-null-pkt-bllp = <0>; //0:blanking packet; 1:Null packet
        panel-dsi-vc = <0x00>; //Virtual channel
        panel-dsi-cmd-type = <0x0>; //0:send in LP mode, 1:send in HS mode
        panel-dsi-clk = <400>;

        panel-init-list =  //delay, type, data, parameters, end symbol
                          < 0x00 0x39 0xFF 0x98 0x81 0x03 0xFFF
                            0x00 0x15 0x01 0x00 0xFFF
                            0x00 0x15 0x02 0x00 0xFFF
                            0x00 0x15 0x03 0x73 0xFFF
                            0x00 0x15 0x04 0x00 0xFFF
                            0x00 0x15 0x05 0x00 0xFFF
                            0x00 0x15 0x06 0x0C 0xFFF
                            0x00 0x15 0x07 0x00 0xFFF
                            0x00 0x15 0x08 0x00 0xFFF
                            0x00 0x15 0x09 0x01 0xFFF
                            0x00 0x15 0x0A 0x01 0xFFF
                            0x00 0x15 0x0B 0x01 0xFFF
                            0x00 0x15 0x0C 0x01 0xFFF
                            0x00 0x15 0x0D 0x01 0xFFF
                            0x00 0x15 0x0E 0x01 0xFFF
                            0x00 0x15 0x0F 0x00 0xFFF
                            0x00 0x15 0x10 0x00 0xFFF
                            0x00 0x15 0x11 0x00 0xFFF
                            0x00 0x15 0x12 0x00 0xFFF
                            0x00 0x15 0x13 0x00 0xFFF
                            0x00 0x15 0x14 0x00 0xFFF
                            0x00 0x15 0x15 0x08 0xFFF
                            0x00 0x15 0x16 0x08 0xFFF
                            0x00 0x15 0x17 0x00 0xFFF
                            0x00 0x15 0x18 0x08 0xFFF
                            0x00 0x15 0x19 0x00 0xFFF
                            0x00 0x15 0x1A 0x00 0xFFF
                            0x00 0x15 0x1B 0x00 0xFFF
                            0x00 0x15 0x1C 0x00 0xFFF
                            0x00 0x15 0x1D 0x00 0xFFF
                            0x00 0x15 0x1E 0x44 0xFFF
                            0x00 0x15 0x1F 0xC0 0xFFF
                            0x00 0x15 0x20 0x0A 0xFFF
                            0x00 0x15 0x21 0x03 0xFFF
                            0x00 0x15 0x22 0x0A 0xFFF
                            0x00 0x15 0x23 0x00 0xFFF
                            0x00 0x15 0x24 0x8C 0xFFF
                            0x00 0x15 0x25 0x8C 0xFFF
                            0x00 0x15 0x26 0x00 0xFFF
                            0x00 0x15 0x27 0x00 0xFFF
                            0x00 0x15 0x28 0x33 0xFFF
                            0x00 0x15 0x29 0x03 0xFFF
                            0x00 0x15 0x2A 0x00 0xFFF
                            0x00 0x15 0x2B 0x00 0xFFF
                            0x00 0x15 0x2C 0x00 0xFFF
                            0x00 0x15 0x2D 0x00 0xFFF
                            0x00 0x15 0x2E 0x00 0xFFF
                            0x00 0x15 0x2F 0x00 0xFFF
                            0x00 0x15 0x30 0x00 0xFFF
                            0x00 0x15 0x31 0x00 0xFFF
                            0x00 0x15 0x32 0x00 0xFFF
                            0x00 0x15 0x33 0x00 0xFFF
                            0x00 0x15 0x34 0x00 0xFFF
                            0x00 0x15 0x35 0x00 0xFFF
                            0x00 0x15 0x36 0x00 0xFFF
                            0x00 0x15 0x37 0x00 0xFFF
                            0x00 0x15 0x38 0x00 0xFFF
                            0x00 0x15 0x39 0x35 0xFFF
                            0x00 0x15 0x3A 0x01 0xFFF
                            0x00 0x15 0x3B 0x40 0xFFF
                            0x00 0x15 0x3C 0x00 0xFFF
                            0x00 0x15 0x3D 0x01 0xFFF
                            0x00 0x15 0x3E 0x00 0xFFF
                            0x00 0x15 0x3F 0x00 0xFFF
                            0x00 0x15 0x40 0x00 0xFFF
                            0x00 0x15 0x41 0x88 0xFFF
                            0x00 0x15 0x42 0x00 0xFFF
                            0x00 0x15 0x43 0x00 0xFFF
                            0x00 0x15 0x44 0x1F 0xFFF
                            0x00 0x15 0x50 0x01 0xFFF
                            0x00 0x15 0x51 0x23 0xFFF
                            0x00 0x15 0x52 0x45 0xFFF
                            0x00 0x15 0x53 0x67 0xFFF
                            0x00 0x15 0x54 0x89 0xFFF
                            0x00 0x15 0x55 0xab 0xFFF
                            0x00 0x15 0x56 0x01 0xFFF
                            0x00 0x15 0x57 0x23 0xFFF
                            0x00 0x15 0x58 0x45 0xFFF
                            0x00 0x15 0x59 0x67 0xFFF
                            0x00 0x15 0x5a 0x89 0xFFF
                            0x00 0x15 0x5b 0xab 0xFFF
                            0x00 0x15 0x5c 0xcd 0xFFF
                            0x00 0x15 0x5d 0xef 0xFFF
                            0x00 0x15 0x5e 0x11 0xFFF
                            0x00 0x15 0x5f 0x0C 0xFFF
                            0x00 0x15 0x60 0x0D 0xFFF
                            0x00 0x15 0x61 0x0E 0xFFF
                            0x00 0x15 0x62 0x0F 0xFFF
                            0x00 0x15 0x63 0x06 0xFFF
                            0x00 0x15 0x64 0x07 0xFFF
                            0x00 0x15 0x65 0x02 0xFFF
                            0x00 0x15 0x66 0x02 0xFFF
                            0x00 0x15 0x67 0x02 0xFFF
                            0x00 0x15 0x68 0x02 0xFFF
                            0x00 0x15 0x69 0x02 0xFFF
                            0x00 0x15 0x6a 0x02 0xFFF
                            0x00 0x15 0x6b 0x02 0xFFF
                            0x00 0x15 0x6c 0x02 0xFFF
                            0x00 0x15 0x6d 0x02 0xFFF
                            0x00 0x15 0x6e 0x02 0xFFF
                            0x00 0x15 0x6f 0x02 0xFFF
                            0x00 0x15 0x70 0x02 0xFFF
                            0x00 0x15 0x71 0x02 0xFFF
                            0x00 0x15 0x72 0x02 0xFFF
                            0x00 0x15 0x73 0x01 0xFFF
                            0x00 0x15 0x74 0x00 0xFFF
                            0x00 0x15 0x75 0x0C 0xFFF
                            0x00 0x15 0x76 0x0D 0xFFF
                            0x00 0x15 0x77 0x0E 0xFFF
                            0x00 0x15 0x78 0x0F 0xFFF
                            0x00 0x15 0x79 0x06 0xFFF
                            0x00 0x15 0x7a 0x07 0xFFF
                            0x00 0x15 0x7b 0x02 0xFFF
                            0x00 0x15 0x7c 0x02 0xFFF
                            0x00 0x15 0x7d 0x02 0xFFF
                            0x00 0x15 0x7e 0x02 0xFFF
                            0x00 0x15 0x7f 0x02 0xFFF
                            0x00 0x15 0x80 0x02 0xFFF
                            0x00 0x15 0x81 0x02 0xFFF
                            0x00 0x15 0x82 0x02 0xFFF
                            0x00 0x15 0x83 0x02 0xFFF
                            0x00 0x15 0x84 0x02 0xFFF
                            0x00 0x15 0x85 0x02 0xFFF
                            0x00 0x15 0x86 0x02 0xFFF
                            0x00 0x15 0x87 0x02 0xFFF
                            0x00 0x15 0x88 0x02 0xFFF
                            0x00 0x15 0x89 0x01 0xFFF
                            0x00 0x15 0x8a 0x00 0xFFF

                            0x00 0x39 0xFF 0x98 0x81 0x04 0xFFF
                            0x00 0x15 0x68 0xDB 0xFFF
                            0x00 0x15 0x6D 0x08 0xFFF
                            0x00 0x15 0x70 0x00 0xFFF
                            0x00 0x15 0x71 0x00 0xFFF
                            0x00 0x15 0x66 0x1E 0xFFF
                            0x00 0x15 0x3a 0x24 0xFFF
                            0x00 0x15 0x82 0x0A 0xFFF
                            0x00 0x15 0x84 0x0A 0xFFF
                            0x00 0x15 0x85 0x16 0xFFF
                            0x00 0x15 0x32 0xAC 0xFFF
                            0x00 0x15 0x8C 0x80 0xFFF
                            0x00 0x15 0x3C 0xF5 0xFFF
                            0x00 0x15 0xB5 0x02 0xFFF
                            0x00 0x15 0x31 0x25 0xFFF
                            0x00 0x15 0x88 0x33 0xFFF

                            0x00 0x39 0xFF 0x98 0x81 0x01 0xFFF
                            0x00 0x15 0x22 0x09 0xFFF
                            0x00 0x15 0x31 0x00 0xFFF
                            0x00 0x15 0x50 0x5C 0xFFF
                            0x00 0x15 0x51 0x5C 0xFFF
                            0x00 0x15 0x53 0x75 0xFFF
                            0x00 0x15 0x55 0x79 0xFFF
                            0x00 0x15 0x60 0x2A 0xFFF
                            0x00 0x15 0x61 0x00 0xFFF
                            0x00 0x15 0x62 0x0D 0xFFF
                            0x00 0x15 0x63 0x00 0xFFF
                            0x00 0x15 0xA0 0x00 0xFFF
                            0x00 0x15 0xA1 0x0B 0xFFF
                            0x00 0x15 0xA2 0x14 0xFFF
                            0x00 0x15 0xA3 0x10 0xFFF
                            0x00 0x15 0xA4 0x12 0xFFF
                            0x00 0x15 0xA5 0x22 0xFFF
                            0x00 0x15 0xA6 0x17 0xFFF
                            0x00 0x15 0xA7 0x1B 0xFFF
                            0x00 0x15 0xA8 0x59 0xFFF
                            0x00 0x15 0xA9 0x1C 0xFFF
                            0x00 0x15 0xAA 0x28 0xFFF
                            0x00 0x15 0xAB 0x4E 0xFFF
                            0x00 0x15 0xAC 0x1A 0xFFF
                            0x00 0x15 0xAD 0x18 0xFFF
                            0x00 0x15 0xAE 0x4E 0xFFF
                            0x00 0x15 0xAF 0x23 0xFFF
                            0x00 0x15 0xB0 0x29 0xFFF
                            0x00 0x15 0xB1 0x46 0xFFF
                            0x00 0x15 0xB2 0x54 0xFFF
                            0x00 0x15 0xB3 0x1C 0xFFF
                            0x00 0x15 0xC0 0x00 0xFFF
                            0x00 0x15 0xC1 0x0B 0xFFF
                            0x00 0x15 0xC2 0x14 0xFFF
                            0x00 0x15 0xC3 0x10 0xFFF
                            0x00 0x15 0xC4 0x12 0xFFF
                            0x00 0x15 0xC5 0x22 0xFFF
                            0x00 0x15 0xC6 0x17 0xFFF
                            0x00 0x15 0xC7 0x1B 0xFFF
                            0x00 0x15 0xC8 0x59 0xFFF
                            0x00 0x15 0xC9 0x1C 0xFFF
                            0x00 0x15 0xCA 0x28 0xFFF
                            0x00 0x15 0xCB 0x4E 0xFFF
                            0x00 0x15 0xCC 0x1A 0xFFF
                            0x00 0x15 0xCD 0x18 0xFFF
                            0x00 0x15 0xCE 0x4E 0xFFF
                            0x00 0x15 0xCF 0x23 0xFFF
                            0x00 0x15 0xD0 0x29 0xFFF
                            0x00 0x15 0xD1 0x46 0xFFF
                            0x00 0x15 0xD2 0x54 0xFFF
                            0x00 0x15 0xD3 0x1C 0xFFF

                            0x00 0x39 0xFF 0x98 0x81 0x00 0xFFF
                            0x00 0x15 0x35 0x00 0xFFF
                            0x78 0x05 0x11 0x00 0xFFF
                            0x0A 0x05 0x29 0x00 0xFFF>;

        status = "disable";
    };
	*/

		sat101at40i28y03:lcd-panel@14 { // for MIPI 4lane
			compatible = "sat,sat101at40i28y03";
			panel-if = <1>; //0 for RGB, 1 for MIPI, 2 for MPU
			panel-rgb-seq = <1>; //0 for BGR, 1 for RGB
			panel-width = <800>;
			panel-height = <1280>;
			panel-pclk-div = <8>; //pixel clock = Peri_pll/(pclk_div+1) <7>;<8>;
			panel-dsi-num-lane = <3>; //0-3: 1lane-4lane
			//0-3: data0-data3, 4: clk
			panel-dsi-txd0 = <0>;
			panel-dsi-txd1 = <1>;
			panel-dsi-txd2 = <4>;
			panel-dsi-txd3 = <2>;
			panel-dsi-txd4 = <3>;

			panel-dsi-noncontinuous-clk = <1>; //0:continuous,1:noncontinuous
			panel-dsi-t-pre = <1>; //t-pre, >=1
			panel-dsi-t-post = <1>; //t-post=tlpx+t-prepare+t-zero+t-pre, >=1
			panel-dsi-tx-gap = <1>; //ths-exit
			panel-dsi-autoinsert-eotp = <0>; //0:not insert,1:auto-insert
			panel-dsi-htx-to-count = <0xFFFFFF>; //high speed TX timeout count
			panel-dsi-lrx-to-count = <0xFFFFFF>; //Low power RX timeout count
			panel-dsi-bta-to-count = <0xFFFFFF>; //Bus turn around timeout count
			panel-dsi-t-wakeup = <0xc8>; //DPHY T-wakeup time
			panel-dsi-pix-fifo-send-level = <512>; //buffer send level <= 512
			//0-2:16-bit config 1-3; 3-4:18-bit config 1-2; 5:24-bit
			panel-dsi-if-color-coding = <0x05>;
			//0:16-bit;1:18-bit;2:18-bit loosely packed;3:24-bit
			panel-dsi-pix-format = <0x03>;
			panel-dsi-vsync-pol = <0>; //0:active low; 1:active high
			panel-dsi-hsync-pol = <0>; //0:active low; 1:active high
			//0:Non-burst mode with sync pulses;
			//1:Noe-burst mode with sync events;
			//2:Burst mode; 3:reserved
			panel-dsi-video-mode = <2>;
			panel-dsi-hfp = <32>;//<20>;<40>; //H front porch blanking packet payload size in bytes
			panel-dsi-hbp = <8>;//<20>;<40>; //H back porch blanking packet payload size in bytes
			panel-dsi-hsa = <8>;//<20>;<40>; //H sync width blanking packet payload size in bytes
			panel-dsi-mult-pkts-en = <0>; //0: single packet;1: two packets
			panel-dsi-vbp = <8>;//<8>;<8>; //V back porch lines
			panel-dsi-vfp = <30>;//<30>;<8>; //V front porch lines
			panel-dsi-vsa = <4>;//<4>;<4>;
			//0:blanking packets send during BLLP;1:LP mode used for BLLP
			panel-dsi-bllp-mode = <1>;
			panel-dsi-use-null-pkt-bllp = <0>; //0:blanking packet; 1:Null packet
			panel-dsi-vc = <0x00>; //Virtual channel
			panel-dsi-cmd-type = <0x0>; //0:send in LP mode, 1:send in HS mode
			panel-dsi-clk = <600>;//<410>;426

			// delay, type, data, parameters, end symbol
			panel-init-list = < 
				0x78 0x39 0xBD 0x00 0x00 0xFFF

				0x00 0x15 0xE0 0x00 0xFFF
				0x00 0x15 0xE1 0x93 0xFFF
				0x00 0x15 0xE2 0x65 0xFFF
				0x00 0x15 0xE3 0xF8 0xFFF
				0x00 0x15 0x80 0x03 0xFFF

				0x00 0x15 0xE0 0x01 0xFFF

				0x00 0x15 0x00 0x00 0xFFF
				0x00 0x15 0x01 0x26 0xFFF

				0x00 0x15 0x17 0x00 0xFFF
				0x00 0x15 0x18 0xD7 0xFFF //4.8v
				0x00 0x15 0x19 0x01 0xFFF //0.3v
				0x00 0x15 0x1A 0x00 0xFFF
				0x00 0x15 0x1B 0xD7 0xFFF //VGMN=0
				0x00 0x15 0x1C 0x01 0xFFF

				0x00 0x15 0x1F 0x70 0xFFF //VGH_REG=16.2V
				0x00 0x15 0x20 0x2D 0xFFF //VGL_REG=-12V
				0x00 0x15 0x21 0x2D 0xFFF //VGL_REG2=-12V
				0x00 0x15 0x22 0x7E 0xFFF
				0x00 0x15 0x24 0xFD 0xFFF

				0x00 0x15 0x37 0x19 0xFFF //SS=1,BGR=1

				0x00 0x15 0x35 0x28 0xFFF //SAP
				// Set RGBCYC
				0x00 0x15 0x38 0x05 0xFFF //JDT=101 zigzag inversion 
				0x00 0x15 0x39 0x08 0xFFF 
				0x00 0x15 0x3A 0x12 0xFFF 
				0x00 0x15 0x3C 0x7E 0xFFF //SET EQ3 for TE_H
				0x00 0x15 0x3D 0xFF 0xFFF //SET CHGEN_ON, modify 20140806
				0x00 0x15 0x3E 0xFF 0xFFF //SET CHGEN_OFF, modify 20140806
				0x00 0x15 0x3F 0x7F 0xFFF //SET CHGEN_OFF2, modify 20140806
				//  Set TCON
				0x00 0x15 0x40 0x06 0xFFF  //RSO 
				0x00 0x15 0x41 0xA0 0xFFF  //LN=640->1280 line
				0x00 0x15 0x43 0x1E 0xFFF  //VFP=0x1E 0x08
				0x00 0x15 0x44 0x0B 0xFFF  //VBP 0x0B 0x08

				//  Power Voltage
				0x00 0x15 0x55 0x02 0xFFF  // DCDCM=1111
				0x00 0x15 0x56 0x01 0xFFF
				0x00 0x15 0x57 0x6A 0xFFF
				0x00 0x15 0x58 0x09 0xFFF
				0x00 0x15 0x59 0x0A 0xFFF  // VCL = -2.5V
				0x00 0x15 0x5A 0x2E 0xFFF  // VGH =16V
				0x00 0x15 0x5B 0x1A 0xFFF  // VGL = -12V
				0x00 0x15 0x5C 0x15 0xFFF  // PUMP CLK
				//  Gamma
				0x00 0x15 0x5D 0x7F 0xFFF
				0x00 0x15 0x5E 0x5D 0xFFF
				0x00 0x15 0x5F 0x4B 0xFFF
				0x00 0x15 0x60 0x3E 0xFFF
				0x00 0x15 0x61 0x3A 0xFFF
				0x00 0x15 0x62 0x2B 0xFFF
				0x00 0x15 0x63 0x2F 0xFFF
				0x00 0x15 0x64 0x19 0xFFF
				0x00 0x15 0x65 0x32 0xFFF
				0x00 0x15 0x66 0x31 0xFFF
				0x00 0x15 0x67 0x31 0xFFF
				0x00 0x15 0x68 0x4F 0xFFF
				0x00 0x15 0x69 0x3E 0xFFF
				0x00 0x15 0x6A 0x47 0xFFF
				0x00 0x15 0x6B 0x36 0xFFF
				0x00 0x15 0x6C 0x31 0xFFF
				0x00 0x15 0x6D 0x24 0xFFF
				0x00 0x15 0x6E 0x12 0xFFF
				0x00 0x15 0x6F 0x02 0xFFF
				0x00 0x15 0x70 0x7F 0xFFF
				0x00 0x15 0x71 0x5D 0xFFF
				0x00 0x15 0x72 0x4B 0xFFF
				0x00 0x15 0x73 0x3E 0xFFF
				0x00 0x15 0x74 0x3A 0xFFF
				0x00 0x15 0x75 0x2B 0xFFF
				0x00 0x15 0x76 0x2F 0xFFF
				0x00 0x15 0x77 0x19 0xFFF
				0x00 0x15 0x78 0x32 0xFFF
				0x00 0x15 0x79 0x31 0xFFF
				0x00 0x15 0x7A 0x31 0xFFF
				0x00 0x15 0x7B 0x4F 0xFFF
				0x00 0x15 0x7C 0x3E 0xFFF
				0x00 0x15 0x7D 0x47 0xFFF
				0x00 0x15 0x7E 0x36 0xFFF
				0x00 0x15 0x7F 0x31 0xFFF
				0x00 0x15 0x80 0x24 0xFFF
				0x00 0x15 0x81 0x12 0xFFF
				0x00 0x15 0x82 0x02 0xFFF
				// page2
				0x00 0x15 0xE0 0x02 0xFFF
				// GIP_L PIN mapping
				0x00 0x15 0x00 0x52 0xFFF
				0x00 0x15 0x01 0x55 0xFFF
				0x00 0x15 0x02 0x55 0xFFF
				0x00 0x15 0x03 0x50 0xFFF
				0x00 0x15 0x04 0x77 0xFFF
				0x00 0x15 0x05 0x57 0xFFF
				0x00 0x15 0x06 0x55 0xFFF
				0x00 0x15 0x07 0x4E 0xFFF
				0x00 0x15 0x08 0x4C 0xFFF
				0x00 0x15 0x09 0x5F 0xFFF
				0x00 0x15 0x0A 0x4A 0xFFF
				0x00 0x15 0x0B 0x48 0xFFF
				0x00 0x15 0x0C 0x55 0xFFF
				0x00 0x15 0x0D 0x46 0xFFF
				0x00 0x15 0x0E 0x44 0xFFF
				0x00 0x15 0x0F 0x40 0xFFF
				0x00 0x15 0x10 0x55 0xFFF
				0x00 0x15 0x11 0x55 0xFFF
				0x00 0x15 0x12 0x55 0xFFF
				0x00 0x15 0x13 0x55 0xFFF
				0x00 0x15 0x14 0x55 0xFFF
				0x00 0x15 0x15 0x55 0xFFF
				// GIP_R PIN mapping
				0x00 0x15 0x16 0x53 0xFFF
				0x00 0x15 0x17 0x55 0xFFF
				0x00 0x15 0x18 0x55 0xFFF
				0x00 0x15 0x19 0x51 0xFFF
				0x00 0x15 0x1A 0x77 0xFFF
				0x00 0x15 0x1B 0x57 0xFFF
				0x00 0x15 0x1C 0x55 0xFFF
				0x00 0x15 0x1D 0x4F 0xFFF
				0x00 0x15 0x1E 0x4D 0xFFF
				0x00 0x15 0x1F 0x5F 0xFFF
				0x00 0x15 0x20 0x4B 0xFFF
				0x00 0x15 0x21 0x49 0xFFF
				0x00 0x15 0x22 0x55 0xFFF
				0x00 0x15 0x23 0x47 0xFFF
				0x00 0x15 0x24 0x45 0xFFF
				0x00 0x15 0x25 0x41 0xFFF
				0x00 0x15 0x26 0x55 0xFFF
				0x00 0x15 0x27 0x55 0xFFF
				0x00 0x15 0x28 0x55 0xFFF
				0x00 0x15 0x29 0x55 0xFFF
				0x00 0x15 0x2A 0x55 0xFFF
				0x00 0x15 0x2B 0x55 0xFFF
				//  GIP_L_GS PIN mapping
				0x00 0x15 0x2C 0x13 0xFFF
				0x00 0x15 0x2D 0x15 0xFFF
				0x00 0x15 0x2E 0x15 0xFFF
				0x00 0x15 0x2F 0x01 0xFFF
				0x00 0x15 0x30 0x37 0xFFF
				0x00 0x15 0x31 0x17 0xFFF
				0x00 0x15 0x32 0x15 0xFFF
				0x00 0x15 0x33 0x0D 0xFFF
				0x00 0x15 0x34 0x0F 0xFFF
				0x00 0x15 0x35 0x15 0xFFF
				0x00 0x15 0x36 0x05 0xFFF
				0x00 0x15 0x37 0x07 0xFFF
				0x00 0x15 0x38 0x15 0xFFF
				0x00 0x15 0x39 0x09 0xFFF
				0x00 0x15 0x3A 0x0B 0xFFF
				0x00 0x15 0x3B 0x11 0xFFF
				0x00 0x15 0x3C 0x15 0xFFF
				0x00 0x15 0x3D 0x15 0xFFF
				0x00 0x15 0x3E 0x15 0xFFF
				0x00 0x15 0x3F 0x15 0xFFF
				0x00 0x15 0x40 0x15 0xFFF
				0x00 0x15 0x41 0x15 0xFFF

				//  GIP_R_GS PIN mapping
				0x00 0x15 0x42 0x12 0xFFF
				0x00 0x15 0x43 0x15 0xFFF
				0x00 0x15 0x44 0x15 0xFFF
				0x00 0x15 0x45 0x00 0xFFF
				0x00 0x15 0x46 0x37 0xFFF
				0x00 0x15 0x47 0x17 0xFFF
				0x00 0x15 0x48 0x15 0xFFF
				0x00 0x15 0x49 0x0C 0xFFF
				0x00 0x15 0x4A 0x0E 0xFFF
				0x00 0x15 0x4B 0x15 0xFFF
				0x00 0x15 0x4C 0x04 0xFFF
				0x00 0x15 0x4D 0x06 0xFFF
				0x00 0x15 0x4E 0x15 0xFFF
				0x00 0x15 0x4F 0x08 0xFFF
				0x00 0x15 0x50 0x0A 0xFFF
				0x00 0x15 0x51 0x10 0xFFF
				0x00 0x15 0x52 0x15 0xFFF
				0x00 0x15 0x53 0x15 0xFFF
				0x00 0x15 0x54 0x15 0xFFF
				0x00 0x15 0x55 0x15 0xFFF
				0x00 0x15 0x56 0x15 0xFFF
				0x00 0x15 0x57 0x15 0xFFF
				// GIP Timing
				0x00 0x15 0x58 0x40 0xFFF
				0x00 0x15 0x5B 0x10 0xFFF
				0x00 0x15 0x5C 0x06 0xFFF
				0x00 0x15 0x5D 0x40 0xFFF
				0x00 0x15 0x5E 0x00 0xFFF
				0x00 0x15 0x5F 0x00 0xFFF
				0x00 0x15 0x60 0x40 0xFFF
				0x00 0x15 0x61 0x03 0xFFF
				0x00 0x15 0x62 0x04 0xFFF
				0x00 0x15 0x63 0x6C 0xFFF
				0x00 0x15 0x64 0x6C 0xFFF
				0x00 0x15 0x65 0x75 0xFFF
				0x00 0x15 0x66 0x08 0xFFF
				0x00 0x15 0x67 0xB4 0xFFF
				0x00 0x15 0x68 0x08 0xFFF
				0x00 0x15 0x69 0x6C 0xFFF
				0x00 0x15 0x6A 0x6C 0xFFF
				0x00 0x15 0x6B 0x0C 0xFFF
				0x00 0x15 0x6D 0x00 0xFFF
				0x00 0x15 0x6E 0x00 0xFFF
				0x00 0x15 0x6F 0x88 0xFFF
				0x00 0x15 0x75 0xBB 0xFFF
				0x00 0x15 0x76 0x00 0xFFF
				0x00 0x15 0x77 0x05 0xFFF
				0x00 0x15 0x78 0x2A 0xFFF
				//  page4
				0x00 0x15 0xE0 0x04 0xFFF
				0x00 0x15 0x09 0x11 0xFFF
				0x00 0x15 0x0E 0x48 0xFFF
				0x00 0x15 0x2D 0x03 0xFFF

				//  page0
				0x00 0x15 0xE0 0x00 0xFFF
				0x00 0x15 0xE6 0x02 0xFFF
				0x00 0x15 0xE7 0x06 0xFFF

				0x78 0x05 0x11 0x00 0xFFF

				0x05 0x05 0x29 0x00 0xFFF

				0x00 0x15 0x35 0x00 0xFFF
				0x00 0x15 0xE0 0x00 0xFFF>;

			status = "disable";
		};
};
